VERSION ""

NS_ :

BS_:

BU_: Bat1 OpticalSensor TelemetryNode Master SensorF SensorR BrakeF BrakeR PDU TestBench MDB1 MDB2 MDB3 MDB4 MDB5 MDB6 Track CLU

BO_ 57 CLU_TX_ActionRequest: 5 CLU
 SG_ CLU_TX_TagetAirGap : 8|32@1+ (1,0) [0|4294967295] "" Vector__XXX
 SG_ CLU_TX_ActionRequest : 0|8@1+ (1,0) [0|255] "" Vector__XXX

BO_ 564 CLU_RX_ActionRequest: 1 SensorF
 SG_ CLU_RX_ActionRequest : 0|8@1+ (1,0) [0|255] ""  SensorF

BO_ 2165346838 BMS44_2_Frame: 8 Vector__XXX
 SG_ BMS44_2_FramePayload : 0|64@1+ (1,0) [0|0] ""  SensorF

BO_ 1792 CLU_RX_StatusLedControll: 1 SensorF
 SG_ CLU_RX_ErrorStatus : 0|1@1+ (1,0) [0|1] ""  CLU

BO_ 592 CLU_TX_LevitationState: 1 CLU
 SG_ CLU_LevitationState : 0|8@1+ (1,0) [0|255] ""  SensorF

BO_ 768 CLU_TX_CoolingState: 1 Vector__XXX
 SG_ CLU_RequiresCooling : 0|1@1+ (1,0) [0|1] ""  SensorF

BO_ 274 MDB3_RX_TargetAirGap: 4 CLU
 SG_ MDB3_TargetAirGap : 0|32@1+ (1,0) [0|0] "" Vector__XXX

BO_ 295 MDB6_RX_TargetAirGap: 4 CLU
 SG_ MDB6_TargetAirGap : 0|32@1+ (1,0) [0|0] "" Vector__XXX

BO_ 297 MDB6_TX_Temperature: 4 Vector__XXX
 SG_ MDB6_Temperature : 0|32@1+ (1,0) [0|0] ""  CLU

BO_ 294 MDB6_TX_AirGap: 4 Vector__XXX
 SG_ MDB6_TargetAirGap : 0|32@1+ (1,0) [0|0] ""  CLU

BO_ 293 MDB6_TX_State: 1 Vector__XXX
 SG_ MDB6_State : 0|8@1+ (1,0) [0|255] ""  CLU

BO_ 292 MDB5_TX_Temperature: 4 Vector__XXX
 SG_ MDB5_Temperature : 0|32@1+ (1,0) [0|0] ""  CLU

BO_ 290 MDB5_RX_TargetAirGap: 4 CLU
 SG_ MDB5_TargetAirGap : 0|32@1+ (1,0) [0|0] "" Vector__XXX

BO_ 289 MDB5_TX_AirGap: 4 Vector__XXX
 SG_ MDB5_AirGap : 0|32@1+ (1,0) [0|0] ""  CLU

BO_ 288 MDB5_TX_State: 1 Vector__XXX
 SG_ MDB5_State : 0|8@1+ (1,0) [0|255] ""  CLU

BO_ 281 MDB4_TX_Temperature: 4 Vector__XXX
 SG_ MDB4_Temperature : 0|32@1+ (1,0) [0|0] ""  CLU

BO_ 279 MDB4_RX_TargetAirGap: 4 CLU
 SG_ MDB4_TargetAirGap : 0|32@1+ (1,0) [0|0] "" Vector__XXX

BO_ 278 MDB4_TX_AirGap: 4 Vector__XXX
 SG_ MDB4_AirGap : 0|32@1+ (1,0) [0|0] ""  CLU

BO_ 277 MDB4_TX_State: 1 Vector__XXX
 SG_ MDB4_State : 0|8@1+ (1,0) [0|255] ""  CLU

BO_ 276 MDB3_TX_Temperature: 4 Vector__XXX
 SG_ MDB3_Temperature : 0|32@1+ (1,0) [0|0] ""  CLU

BO_ 273 MDB3_TX_AirGap: 4 Vector__XXX
 SG_ MDB3_AirGap : 0|32@1+ (1,0) [0|0] ""  CLU

BO_ 272 MDB3_TX_State: 1 Vector__XXX
 SG_ MDB3_State : 0|8@1+ (1,0) [0|255] ""  CLU

BO_ 265 MDB2_TX_Temperature: 4 Vector__XXX
 SG_ MDB2_Temperature : 0|32@1+ (1,0) [0|0] ""  CLU

BO_ 263 MDB2_RX_TargetAirGap: 4 CLU
 SG_ MDB2_TargetAirGap : 0|32@1+ (1,0) [0|0] "" Vector__XXX

BO_ 262 MDB2_TX_AirGap: 4 Vector__XXX
 SG_ MDB2_AirGap : 0|32@1+ (1,0) [0|0] ""  CLU

BO_ 261 MDB2_TX_State: 1 Vector__XXX
 SG_ MDB2_State : 0|8@1+ (1,0) [0|255] ""  CLU

BO_ 258 MDB1_RX_TargetAirGap: 4 CLU
 SG_ MDB1_TargetAirGap : 0|32@1+ (1,0) [0|0] "" Vector__XXX

BO_ 260 MDB1_TX_Temperature: 4 MDB3
 SG_ MDB1_Temperature : 0|32@1+ (1,0) [0|0] ""  CLU,SensorF

BO_ 257 MDB1_TX_AirGap: 4 MDB3
 SG_ MDB1_AirGap : 0|32@1+ (1,0) [0|0] ""  CLU

BO_ 1041 BrakeF_TX_PressureCooling: 2 BrakeF
 SG_ BrakeF_TX_Pressure_Reservoir : 0|12@1+ (0.005,-2) [-2|18.475] "bar"  SensorF

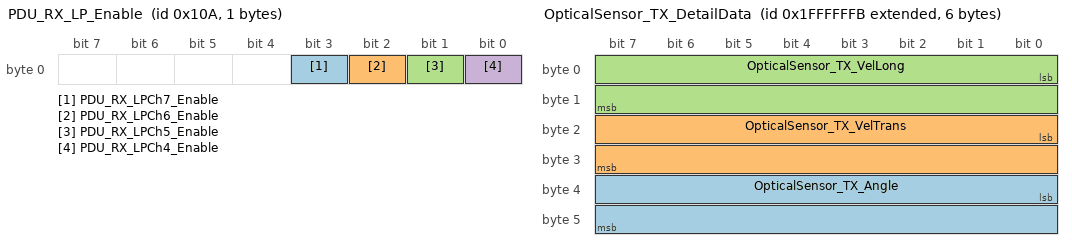
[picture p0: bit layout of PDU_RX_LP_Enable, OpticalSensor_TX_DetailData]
BO_ 266 PDU_RX_LP_Enable: 1 PDU
 SG_ PDU_RX_LPCh7_Enable : 3|1@1+ (1,0) [0|1] ""  SensorF
 SG_ PDU_RX_LPCh6_Enable : 2|1@1+ (1,0) [0|1] ""  SensorF
 SG_ PDU_RX_LPCh5_Enable : 1|1@1+ (1,0) [0|1] ""  SensorF
 SG_ PDU_RX_LPCh4_Enable : 0|1@1+ (1,0) [0|1] ""  SensorF

BO_ 2148592864 BMS44_1_Frame: 8 Bat1
 SG_ BMS44_1_FramePayload : 0|64@1+ (1,0) [0|0] ""  SensorF

BO_ 1 Track_TX_Respond: 1 Track
 SG_ Track_TX_Response : 0|8@1+ (1,0) [0|255] ""  SensorF

BO_ 0 Track_RX_Controll: 1 SensorF
 SG_ Track_RX_Command : 0|8@1+ (1,0) [0|255] "" Vector__XXX

BO_ 512 TEST_GROUND_STATION_CONTROLL: 1 Vector__XXX
 SG_ TEST_GROUND_STATION_COMMAND : 0|8@1+ (1,0) [0|255] ""  SensorF

BO_ 256 MDB1_TX_State: 1 MDB3
 SG_ MDB1_State : 0|8@1+ (1,0) [0|255] ""  CLU,SensorF

BO_ 450 SensorR_RX_POD1: 8 Vector__XXX

BO_ 2684354555 OpticalSensor_TX_DetailData: 6 OpticalSensor
 SG_ OpticalSensor_TX_Angle : 32|16@1- (0.01,0) [-45|45] "�" Vector__XXX
 SG_ OpticalSensor_TX_VelTrans : 16|16@1- (0.036,0) [-200|200] "km/h" Vector__XXX
 SG_ OpticalSensor_TX_VelLong : 0|16@1+ (0.036,0) [0|400] "km/h" Vector__XXX

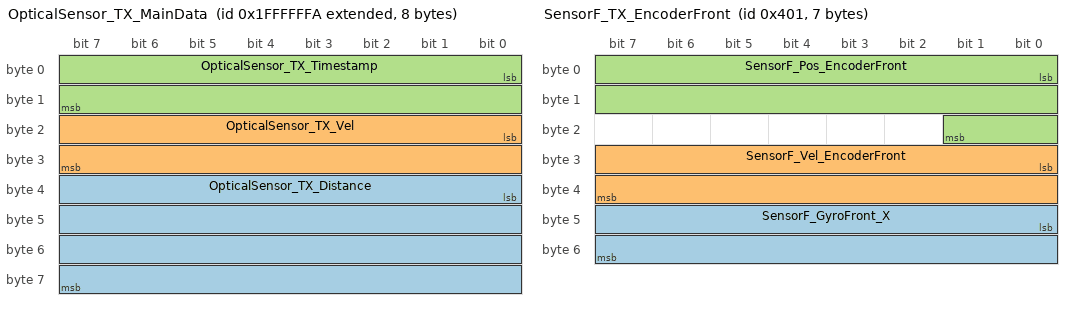
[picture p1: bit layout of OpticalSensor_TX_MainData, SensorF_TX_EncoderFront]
BO_ 2684354554 OpticalSensor_TX_MainData: 8 OpticalSensor
 SG_ OpticalSensor_TX_Distance : 32|32@1+ (0.001,0) [0|4294970] "m"  SensorF,SensorR
 SG_ OpticalSensor_TX_Vel : 16|16@1+ (0.036,0) [0|400] "km/h"  SensorF,SensorR
 SG_ OpticalSensor_TX_Timestamp : 0|16@1+ (1,0) [0|65535] ""  SensorF,SensorR

BO_ 2684354556 OpticalSensor_TX_Status: 8 OpticalSensor
 SG_ OpticalSensor_TX_VddOK : 62|1@1+ (1,0) [0|0] ""  SensorF
 SG_ OpticalSensor_TX_VeeOK : 61|1@1+ (1,0) [0|0] ""  SensorF
 SG_ OpticalSensor_TX_V33OK : 60|1@1+ (1,0) [0|0] ""  SensorF
 SG_ OpticalSensor_TX_V25OK : 59|1@1+ (1,0) [0|0] ""  SensorF
 SG_ OpticalSensor_TX_LEDStatus : 57|2@1+ (1,0) [0|0] ""  SensorF
 SG_ OpticalSensor_TX_LED_Cal : 56|1@1+ (1,0) [0|0] ""  SensorF
 SG_ OpticalSensor_TX_PowerOK : 55|1@1+ (1,0) [0|0] ""  SensorF
 SG_ OpticalSensor_TX_CurrentOK : 54|1@1+ (1,0) [0|0] ""  SensorF
 SG_ OpticalSensor_TX_CurrentLowHigh : 53|1@1+ (1,0) [0|0] ""  SensorF
 SG_ OpticalSensor_TX_OpticOK : 52|1@1+ (1,0) [0|0] ""  SensorF
 SG_ OpticalSensor_TX_TempOK : 51|1@1+ (1,0) [0|0] ""  SensorF
 SG_ OpticalSensor_TX_SensorOK : 50|1@1+ (1,0) [0|0] ""  SensorF
 SG_ OpticalSensor_TX_SelfTest : 49|1@1+ (1,0) [0|0] ""  SensorF
 SG_ OpticalSensor_TX_STST : 48|1@1+ (1,0) [0|0] ""  SensorF
 SG_ OpticalSensor_TX_LEDCurrent : 40|8@1+ (0.01,0) [0|2.55] "A"  SensorF
 SG_ OpticalSensor_TX_Temp : 32|8@1- (1,0) [-128|127] "�C"  SensorF
 SG_ OpticalSensor_TX_SensorNo : 24|8@1+ (1,0) [0|0] ""  SensorF
 SG_ OpticalSensor_TX_SerialNo : 0|24@1+ (1,0) [0|0] ""  SensorF

BO_ 2 CANzero_NMT: 4 Master
 SG_ CANzero_NMT_Node : 16|16@1+ (1,0) [0|63] ""  SensorF,SensorR,BrakeF,BrakeR,PDU,TelemetryNode,MDB1,MDB2,MDB3,MDB4,MDB5,MDB6,Track,CLU
 SG_ CANzero_NMT_State : 0|16@1+ (1,0) [0|0] ""  SensorF,SensorR,BrakeF,BrakeR,PDU,TelemetryNode,MDB1,MDB2,MDB3,MDB4,MDB5,MDB6,Track,CLU

BO_ 122 CANzero_Sync: 0 Master

BO_ 123 CANzero_Timestamp: 0 Master

BO_ 129 SensorF_EMCY: 4 SensorF

BO_ 385 SensorF_TX_StatePod: 1 SensorF
 SG_ SensorF_TX_PodState : 0|8@1+ (1,0) [0|255] ""  CLU,Track,BrakeF,PDU

BO_ 449 SensorF_RX_PDO1: 0 Vector__XXX

BO_ 513 SensorF_TX_FSMTransitions: 4 SensorF
 SG_ SensorF_TX_PreopHVCUT : 24|1@1+ (1,0) [0|0] "" Vector__XXX
 SG_ SensorF_TX_PreopPDUT : 16|1@1+ (1,0) [0|0] "" Vector__XXX
 SG_ SensorF_TX_PreopBrakeRT : 15|1@1+ (1,0) [0|0] "" Vector__XXX
 SG_ SensorF_TX_PreopBrakeFT : 14|1@1+ (1,0) [0|0] "" Vector__XXX
 SG_ SensorF_TX_PreopSensorRT : 13|1@1+ (1,0) [0|0] "" Vector__XXX
 SG_ SensorF_TX_EnableSensorRT : 12|1@1+ (1,0) [0|0] "" Vector__XXX
 SG_ SensorF_TX_EnablePDUT : 11|1@1+ (1,0) [0|0] "" Vector__XXX
 SG_ SensorF_TX_EnableHVCUT : 10|1@1+ (1,0) [0|0] "" Vector__XXX
 SG_ SensorF_TX_EnableBrakeRT : 9|1@1+ (1,0) [0|0] "" Vector__XXX
 SG_ SensorF_TX_EnableBrakeFT : 8|1@1+ (1,0) [0|0] "" Vector__XXX
 SG_ SensorF_TX_SetHVTransition : 7|1@1+ (1,0) [0|0] "" Vector__XXX
 SG_ SensorF_TX_PreopTransition : 6|1@1+ (1,0) [0|0] "" Vector__XXX
 SG_ SensorF_TX_LaunchStartTransition : 5|1@1+ (1,0) [0|0] "" Vector__XXX
 SG_ SensorF_TX_LaunchSetupTransition : 4|1@1+ (1,0) [0|0] "" Vector__XXX
 SG_ SensorF_TX_HWEnableTransition : 3|1@1+ (1,0) [0|0] "" Vector__XXX
 SG_ SensorF_TX_ErrorResetTransition : 2|1@1+ (1,0) [0|0] "" Vector__XXX
 SG_ SensorF_TX_EnableTransition : 1|1@1+ (1,0) [0|0] "" Vector__XXX
 SG_ SensorF_TX_BrakesTransition : 0|1@1+ (1,0) [0|0] "" Vector__XXX

BO_ 577 SensorF_RX_PDO2: 0 Vector__XXX

BO_ 641 SensorF_TX_PDO3: 0 SensorF

BO_ 705 SensorF_RX_PDO3: 0 Vector__XXX

BO_ 769 SensorF_TX_PDO4: 0 SensorF

BO_ 833 SensorF_RX_PDO4: 0 Vector__XXX

BO_ 897 SensorF_TX_PDO5: 0 SensorF

BO_ 961 SensorF_TX_PDO6: 0 SensorF

BO_ 1025 SensorF_TX_EncoderFront: 7 SensorF
 SG_ SensorF_GyroFront_X : 40|16@1- (0.017,0) [-557.056|557.039] "°/s"  SensorR
 SG_ SensorF_Vel_EncoderFront : 24|16@1- (0.002,0) [-65.536|65.534] "m/s"  SensorR
 SG_ SensorF_Pos_EncoderFront : 0|18@1- (0.005,0) [-655.36|655.355] "m"  SensorR

BO_ 1089 SensorF_TX_BMS: 2 SensorF
 SG_ SensorF_TX_BatteryTemp : 0|12@1+ (0.05,-30) [-30|174.75] "C"  PDU

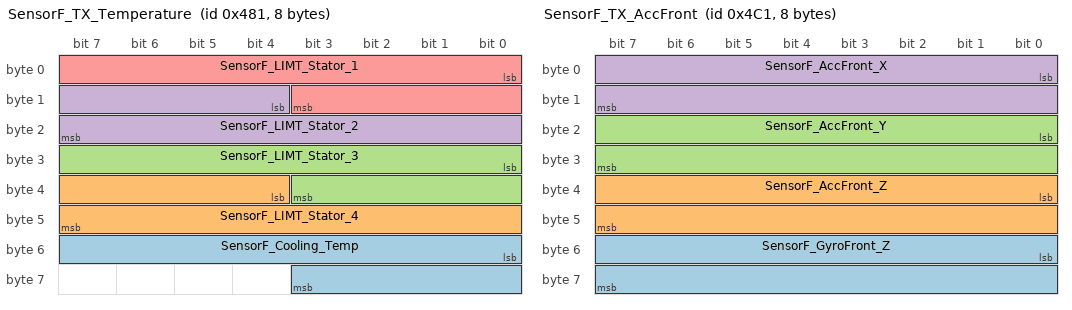
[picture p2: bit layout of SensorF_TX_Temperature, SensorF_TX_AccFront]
BO_ 1153 SensorF_TX_Temperature: 8 SensorF
 SG_ SensorF_Cooling_Temp : 48|12@1+ (0.05,-30) [-30|174.75] "C"  PDU
 SG_ SensorF_LIMT_Stator_4 : 36|12@1+ (0.075,-20) [-20|287.125] "�C" Vector__XXX
 SG_ SensorF_LIMT_Stator_3 : 24|12@1+ (0.075,-20) [-20|287.125] "�C" Vector__XXX
 SG_ SensorF_LIMT_Stator_2 : 12|12@1+ (0.075,-20) [-20|287.125] "�C" Vector__XXX
 SG_ SensorF_LIMT_Stator_1 : 0|12@1+ (0.075,-20) [-20|287.125] "�C" Vector__XXX

BO_ 1217 SensorF_TX_AccFront: 8 SensorF
 SG_ SensorF_GyroFront_Z : 48|16@1- (0.017,0) [-557.056|557.039] "°/s"  SensorR
 SG_ SensorF_AccFront_Z : 32|16@1- (0.00125,0) [-40.96|40.95875] "m/s^2"  SensorR
 SG_ SensorF_AccFront_Y : 16|16@1- (0.00125,0) [-40.96|40.95875] "m/s^2"  SensorR
 SG_ SensorF_AccFront_X : 0|16@1- (0.00125,0) [-40.96|40.95875] "m/s^2"  SensorR

BO_ 1281 SensorF_TX_PDO11: 0 SensorF

BO_ 1345 SensorF_TX_PDO12: 0 SensorF

BO_ 1409 SensorF_SDO_Resp: 8 SensorF
 SG_ SensorF_SDO_RespCode : 12|4@1+ (1,0) [0|0] ""  TelemetryNode
 SG_ SensorF_SDO_ID M : 0|12@1+ (1,0) [0|4095] ""  TelemetryNode

BO_ 1473 SensorF_SDO_Req_Up: 8 TelemetryNode
 SG_ SensorF_SDO_ID M : 0|12@1+ (1,0) [0|4095] ""  SensorF

BO_ 1537 SensorF_SDO_Req_Down: 2 TelemetryNode
 SG_ SensorF_SDO_ID M : 0|12@1+ (1,0) [0|4095] ""  SensorF

BO_ 1793 SensorF_Heartbeat: 1 SensorF
 SG_ SensorF_NodeState : 0|8@1+ (1,0) [0|0] ""  SensorF,Master,TelemetryNode

BO_ 1857 SensorF_BTL_TX: 8 SensorF

BO_ 1921 SensorF_BTL_RX: 8 TelemetryNode

BO_ 130 SensorR_EMCY: 4 SensorR

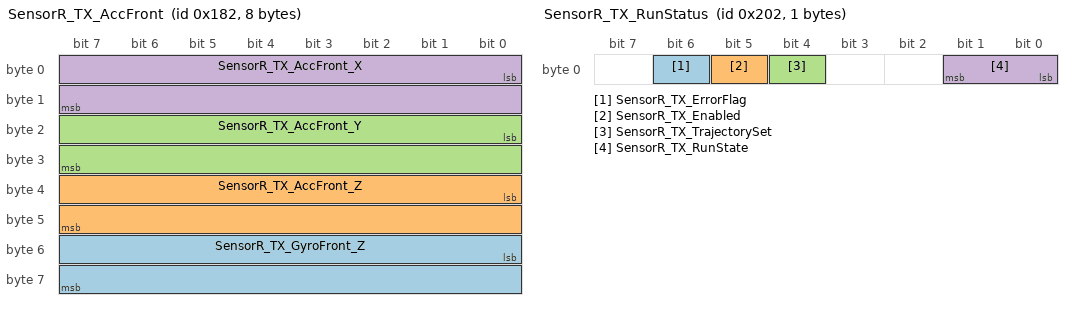
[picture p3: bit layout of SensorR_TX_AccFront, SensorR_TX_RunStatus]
BO_ 386 SensorR_TX_AccFront: 8 SensorR
 SG_ SensorR_TX_GyroFront_Z : 48|16@1- (0.017,0) [-557.056|557.039] "°/s" Vector__XXX
 SG_ SensorR_TX_AccFront_Z : 32|16@1- (0.00125,0) [-40.96|40.95875] "m/s^2" Vector__XXX
 SG_ SensorR_TX_AccFront_Y : 16|16@1- (0.00125,0) [-40.96|40.95875] "m/s^2" Vector__XXX
 SG_ SensorR_TX_AccFront_X : 0|16@1- (0.00125,0) [-40.96|40.95875] "m/s^2" Vector__XXX

BO_ 514 SensorR_TX_RunStatus: 1 SensorR
 SG_ SensorR_TX_ErrorFlag : 6|1@1+ (1,0) [0|0] "" Vector__XXX
 SG_ SensorR_TX_Enabled : 5|1@1+ (1,0) [0|0] "" Vector__XXX
 SG_ SensorR_TX_TrajectorySet : 4|1@1+ (1,0) [0|0] "" Vector__XXX
 SG_ SensorR_TX_RunState : 0|2@1+ (1,0) [0|0] ""  PDU

BO_ 578 SensorR_RX_PDO2: 0 Vector__XXX

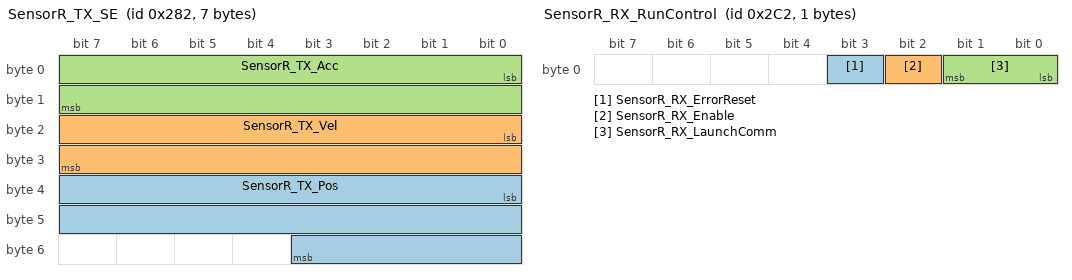
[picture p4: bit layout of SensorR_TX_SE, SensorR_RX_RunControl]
BO_ 642 SensorR_TX_SE: 7 SensorR
 SG_ SensorR_TX_Pos : 32|20@1- (0.001,0) [-524.288|524.287] "m"  PDU,TelemetryNode
 SG_ SensorR_TX_Vel : 16|16@1- (0.002,0) [-65.536|65.534] "m/s"  PDU,TelemetryNode
 SG_ SensorR_TX_Acc : 0|16@1- (0.00125,0) [-40.96|40.95875] "m/s^2"  PDU,TelemetryNode

BO_ 706 SensorR_RX_RunControl: 1 SensorF
 SG_ SensorR_RX_ErrorReset : 3|1@1+ (1,0) [0|0] "" Vector__XXX
 SG_ SensorR_RX_Enable : 2|1@1+ (1,0) [0|0] "" Vector__XXX
 SG_ SensorR_RX_LaunchComm : 0|2@1+ (1,0) [0|0] "" Vector__XXX

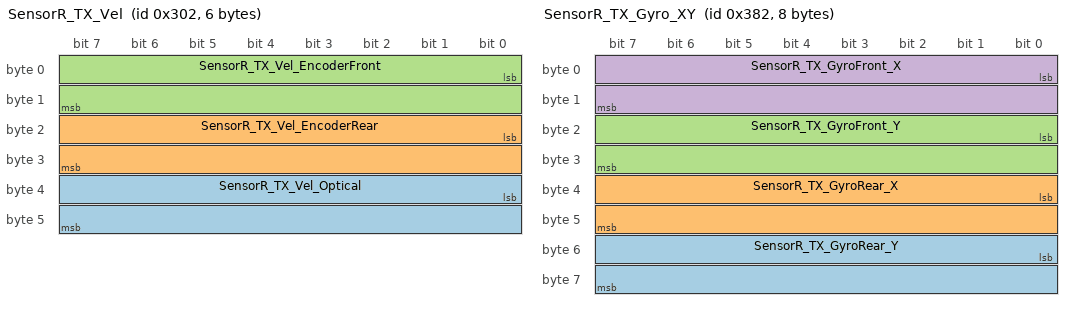
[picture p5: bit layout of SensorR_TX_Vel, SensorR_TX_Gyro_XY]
BO_ 770 SensorR_TX_Vel: 6 SensorR
 SG_ SensorR_TX_Vel_Optical : 32|16@1- (0.002,0) [-65.536|65.534] "m/s" Vector__XXX
 SG_ SensorR_TX_Vel_EncoderRear : 16|16@1- (0.002,0) [-65.536|65.534] "m/s" Vector__XXX
 SG_ SensorR_TX_Vel_EncoderFront : 0|16@1- (0.002,0) [-65.536|65.534] "m/s" Vector__XXX

BO_ 834 SensorR_RX_PDO4: 0 Vector__XXX

BO_ 898 SensorR_TX_Gyro_XY: 8 SensorR
 SG_ SensorR_TX_GyroRear_Y : 48|16@1- (0.017,0) [-557.056|557.039] "°/s" Vector__XXX
 SG_ SensorR_TX_GyroRear_X : 32|16@1- (0.017,0) [-557.056|557.039] "°/s" Vector__XXX
 SG_ SensorR_TX_GyroFront_Y : 16|16@1- (0.017,0) [-557.056|557.039] "°/s" Vector__XXX
 SG_ SensorR_TX_GyroFront_X : 0|16@1- (0.017,0) [-557.056|557.039] "°/s" Vector__XXX

BO_ 962 SensorR_TX_TargetValues: 2 SensorR
 SG_ SensorR_TX_TargetVelocity : 0|14@1- (0.01,0) [-81.92|81.91] "m/s" Vector__XXX

BO_ 1026 SensorR_TX_GapHeight: 4 SensorR
 SG_ SensorR_TX_GapHeight_Right : 12|12@1- (0.0125,0) [-25.6|25.5875] "mm" Vector__XXX
 SG_ SensorR_TX_GapHeight_Left : 0|12@1- (0.0125,0) [-25.6|25.5875] "mm" Vector__XXX

BO_ 1090 SensorR_TX_PDO8: 0 SensorR

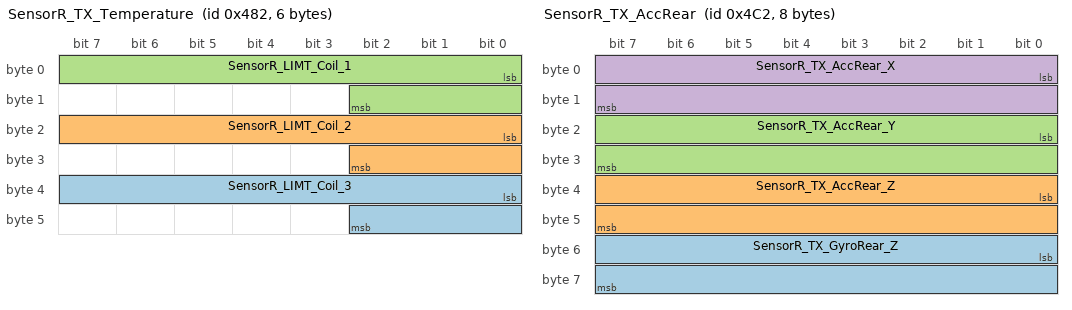
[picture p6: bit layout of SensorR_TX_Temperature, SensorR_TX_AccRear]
BO_ 1154 SensorR_TX_Temperature: 6 SensorR
 SG_ SensorR_LIMT_Coil_3 : 32|11@1+ (0.1,-5) [-5|199.7] "�C"  PDU
 SG_ SensorR_LIMT_Coil_2 : 16|11@1+ (0.1,-5) [-5|199.7] "�C"  PDU
 SG_ SensorR_LIMT_Coil_1 : 0|11@1+ (0.1,-5) [-5|199.7] "�C"  PDU

BO_ 1218 SensorR_TX_AccRear: 8 SensorR
 SG_ SensorR_TX_GyroRear_Z : 48|16@1- (0.017,0) [-557.056|557.039] "°/s" Vector__XXX
 SG_ SensorR_TX_AccRear_Z : 32|16@1- (0.00125,0) [-40.96|40.95875] "m/s^2" Vector__XXX
 SG_ SensorR_TX_AccRear_Y : 16|16@1- (0.00125,0) [-40.96|40.95875] "m/s^2" Vector__XXX
 SG_ SensorR_TX_AccRear_X : 0|16@1- (0.00125,0) [-40.96|40.95875] "m/s^2" Vector__XXX

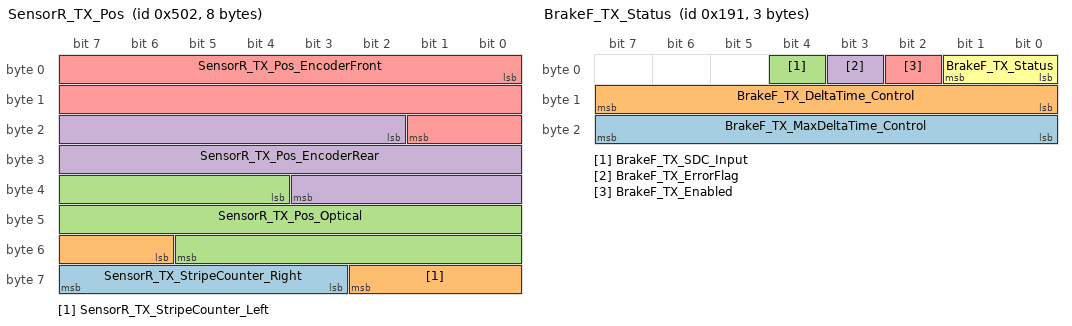
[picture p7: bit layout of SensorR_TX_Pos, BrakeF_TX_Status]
BO_ 1282 SensorR_TX_Pos: 8 SensorR
 SG_ SensorR_TX_StripeCounter_Right : 59|5@1+ (1,0) [0|31] "" Vector__XXX
 SG_ SensorR_TX_StripeCounter_Left : 54|5@1+ (1,0) [0|31] "" Vector__XXX
 SG_ SensorR_TX_Pos_Optical : 36|18@1- (0.005,0) [-655.36|655.355] "m" Vector__XXX
 SG_ SensorR_TX_Pos_EncoderRear : 18|18@1- (0.005,0) [-655.36|655.355] "m" Vector__XXX
 SG_ SensorR_TX_Pos_EncoderFront : 0|18@1- (0.005,0) [-655.36|655.355] "m" Vector__XXX

BO_ 1346 SensorR_TX_PDO12: 0 SensorR

BO_ 1410 SensorR_SDO_Resp: 8 SensorR
 SG_ SensorR_SDO_RespCode : 12|4@1+ (1,0) [0|0] ""  TelemetryNode
 SG_ SensorR_SDO_ID M : 0|12@1+ (1,0) [0|4095] ""  PDU,TelemetryNode

BO_ 1474 SensorR_SDO_Req_Up: 8 TelemetryNode
 SG_ SensorR_SDO_ID M : 0|12@1+ (1,0) [0|4095] ""  SensorR

BO_ 1538 SensorR_SDO_Req_Down: 2 TelemetryNode
 SG_ SensorR_SDO_ID M : 0|12@1+ (1,0) [0|4095] ""  SensorR

BO_ 1794 SensorR_Heartbeat: 1 SensorR
 SG_ SensorR_NodeState : 0|8@1+ (1,0) [0|0] ""  Master,TelemetryNode

BO_ 1858 SensorR_BTL_TX: 8 SensorR

BO_ 1922 SensorR_BTL_RX: 8 TelemetryNode

BO_ 145 BrakeF_EMCY: 4 BrakeF

BO_ 401 BrakeF_TX_Status: 3 BrakeF
 SG_ BrakeF_TX_MaxDeltaTime_Control : 16|8@1+ (1,0) [0|255] "ms" Vector__XXX
 SG_ BrakeF_TX_DeltaTime_Control : 8|8@1+ (1,0) [0|255] "ms" Vector__XXX
 SG_ BrakeF_TX_SDC_Input : 4|1@1+ (1,0) [0|0] "" Vector__XXX
 SG_ BrakeF_TX_ErrorFlag : 3|1@1+ (1,0) [0|0] ""  SensorF
 SG_ BrakeF_TX_Enabled : 2|1@1+ (1,0) [0|0] ""  SensorF
 SG_ BrakeF_TX_Status : 0|2@1+ (1,0) [0|0] ""  SensorF

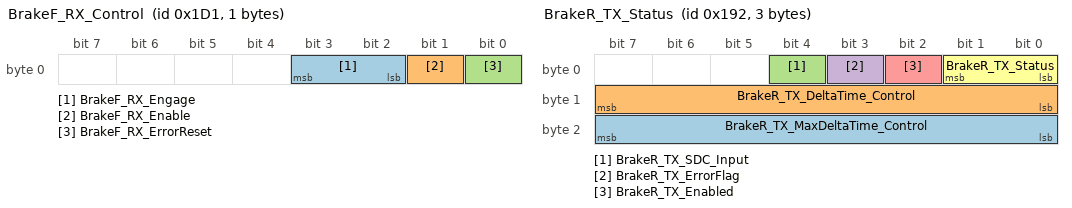
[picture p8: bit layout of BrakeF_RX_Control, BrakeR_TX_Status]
BO_ 465 BrakeF_RX_Control: 1 SensorF
 SG_ BrakeF_RX_Engage : 2|2@1+ (1,0) [0|0] "" Vector__XXX
 SG_ BrakeF_RX_Enable : 1|1@1+ (1,0) [0|0] "" Vector__XXX
 SG_ BrakeF_RX_ErrorReset : 0|1@1+ (1,0) [0|0] "" Vector__XXX

BO_ 529 BrakeF_TX_PDO2: 0 BrakeF

BO_ 593 BrakeF_RX_PDO2: 0 Vector__XXX

BO_ 657 BrakeF_TX_PDO3: 0 BrakeF

BO_ 721 BrakeF_RX_PDO3: 0 Vector__XXX

BO_ 785 BrakeF_TX_PDO4: 0 BrakeF

BO_ 849 BrakeF_RX_PDO4: 0 Vector__XXX

BO_ 913 BrakeF_TX_PDO5: 0 BrakeF

BO_ 977 BrakeF_TX_PDO6: 0 BrakeF

BO_ 1105 BrakeF_TX_PDO8: 0 BrakeF

BO_ 1169 BrakeF_TX_PDO9: 0 BrakeF

BO_ 1233 BrakeF_TX_PDO10: 0 BrakeF

BO_ 1297 BrakeF_TX_PDO11: 0 BrakeF

BO_ 1361 BrakeF_TX_PDO12: 0 BrakeF

BO_ 1425 BrakeF_SDO_Resp: 8 BrakeF
 SG_ BrakeF_SDO_RespCode : 12|4@1+ (1,0) [0|0] ""  TelemetryNode
 SG_ BrakeF_SDO_ID M : 0|12@1+ (1,0) [0|4095] ""  TelemetryNode

BO_ 1489 BrakeF_SDO_Req_Up: 8 TelemetryNode
 SG_ BrakeF_SDO_ID M : 0|12@1+ (1,0) [0|4095] ""  BrakeF

BO_ 1553 BrakeF_SDO_Req_Down: 2 TelemetryNode
 SG_ BrakeF_SDO_ID M : 0|12@1+ (1,0) [0|4095] ""  BrakeF

BO_ 1809 BrakeF_Heartbeat: 1 BrakeF
 SG_ BrakeF_NodeState : 0|8@1+ (1,0) [0|0] ""  SensorF,Master,TelemetryNode

BO_ 1873 BrakeF_BTL_TX: 8 BrakeF

BO_ 1937 BrakeF_BTL_RX: 8 TelemetryNode

BO_ 146 BrakeR_EMCY: 4 BrakeR

BO_ 402 BrakeR_TX_Status: 3 BrakeR
 SG_ BrakeR_TX_MaxDeltaTime_Control : 16|8@1+ (1,0) [0|255] "ms" Vector__XXX
 SG_ BrakeR_TX_DeltaTime_Control : 8|8@1+ (1,0) [0|255] "ms" Vector__XXX
 SG_ BrakeR_TX_SDC_Input : 4|1@1+ (1,0) [0|0] "" Vector__XXX
 SG_ BrakeR_TX_ErrorFlag : 3|1@1+ (1,0) [0|0] "" Vector__XXX
 SG_ BrakeR_TX_Enabled : 2|1@1+ (1,0) [0|0] "" Vector__XXX
 SG_ BrakeR_TX_Status : 0|2@1+ (1,0) [0|0] "" Vector__XXX

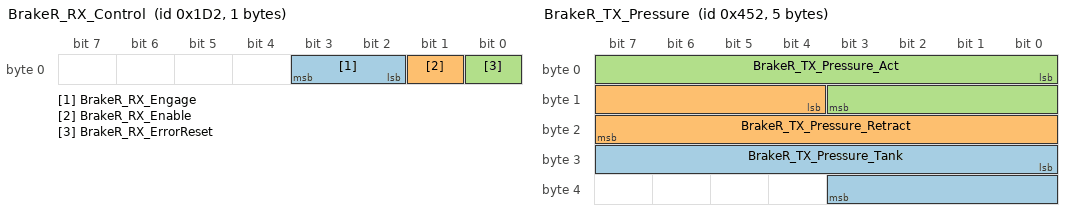
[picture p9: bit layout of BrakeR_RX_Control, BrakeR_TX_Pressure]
BO_ 466 BrakeR_RX_Control: 1 SensorF
 SG_ BrakeR_RX_Engage : 2|2@1+ (1,0) [0|0] "" Vector__XXX
 SG_ BrakeR_RX_Enable : 1|1@1+ (1,0) [0|0] "" Vector__XXX
 SG_ BrakeR_RX_ErrorReset : 0|1@1+ (1,0) [0|0] "" Vector__XXX

BO_ 530 BrakeR_TX_PDO2: 0 BrakeR

BO_ 594 BrakeR_RX_PDO2: 0 Vector__XXX

BO_ 658 BrakeR_TX_PDO3: 0 BrakeR

BO_ 722 BrakeR_RX_PDO3: 0 Vector__XXX

BO_ 786 BrakeR_TX_PDO4: 0 BrakeR

BO_ 850 BrakeR_RX_PDO4: 0 Vector__XXX

BO_ 914 BrakeR_TX_PDO5: 0 BrakeR

BO_ 978 BrakeR_TX_PDO6: 0 BrakeR

BO_ 1042 BrakeR_TX_PDO7: 0 BrakeR

BO_ 1106 BrakeR_TX_Pressure: 5 BrakeR
 SG_ BrakeR_TX_Pressure_Tank : 24|12@1+ (0.005,-2) [-2|18.475] "bar" Vector__XXX
 SG_ BrakeR_TX_Pressure_Retract : 12|12@1+ (0.005,-2) [-2|18.475] "bar" Vector__XXX
 SG_ BrakeR_TX_Pressure_Act : 0|12@1+ (0.005,-2) [-2|18.475] "bar" Vector__XXX

BO_ 1170 BrakeR_TX_PDO9: 0 BrakeR

BO_ 1234 BrakeR_TX_PDO10: 0 BrakeR

BO_ 1298 BrakeR_TX_PDO11: 0 BrakeR

BO_ 1362 BrakeR_TX_PDO12: 0 BrakeR

BO_ 1426 BrakeR_SDO_Resp: 8 BrakeR
 SG_ BrakeR_SDO_RespCode : 12|4@1+ (1,0) [0|0] ""  TelemetryNode
 SG_ BrakeR_SDO_ID M : 0|12@1+ (1,0) [0|4095] ""  TelemetryNode

BO_ 1490 BrakeR_SDO_Req_Up: 8 TelemetryNode
 SG_ BrakeR_SDO_ID M : 0|12@1+ (1,0) [0|4095] ""  BrakeR

BO_ 1554 BrakeR_SDO_Req_Down: 2 TelemetryNode
 SG_ BrakeR_SDO_ID M : 0|12@1+ (1,0) [0|4095] ""  BrakeR

BO_ 1810 BrakeR_Heartbeat: 1 BrakeR
 SG_ BrakeR_NodeState : 0|8@1+ (1,0) [0|0] ""  Master,TelemetryNode

BO_ 1874 BrakeR_BTL_TX: 8 BrakeR

BO_ 1938 BrakeR_BTL_RX: 8 TelemetryNode

BO_ 154 PDU_EMCY: 4 PDU

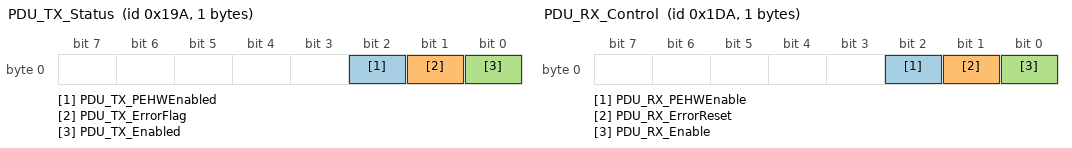
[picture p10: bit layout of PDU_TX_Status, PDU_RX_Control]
BO_ 410 PDU_TX_Status: 1 PDU
 SG_ PDU_TX_PEHWEnabled : 2|1@1+ (1,0) [0|0] ""  SensorF
 SG_ PDU_TX_ErrorFlag : 1|1@1+ (1,0) [0|0] ""  SensorF
 SG_ PDU_TX_Enabled : 0|1@1+ (1,0) [0|0] ""  SensorF

BO_ 474 PDU_RX_Control: 1 SensorF
 SG_ PDU_RX_PEHWEnable : 2|1@1+ (1,0) [0|0] ""  PDU
 SG_ PDU_RX_ErrorReset : 1|1@1+ (1,0) [0|0] ""  PDU
 SG_ PDU_RX_Enable : 0|1@1+ (1,0) [0|0] ""  PDU

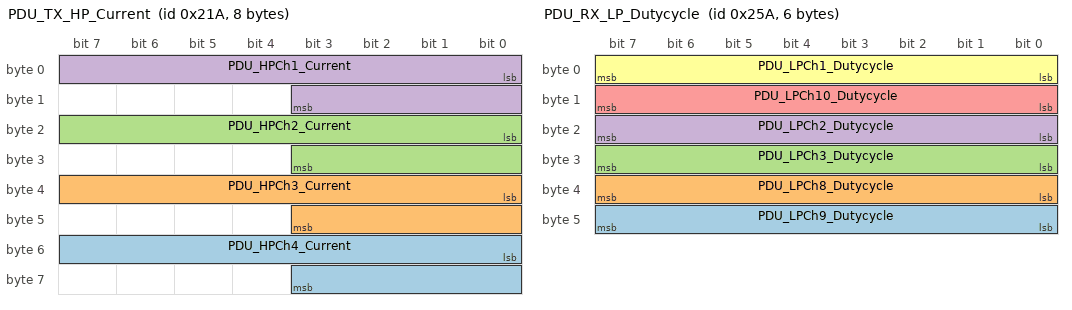
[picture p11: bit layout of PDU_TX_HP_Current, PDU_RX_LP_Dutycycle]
BO_ 538 PDU_TX_HP_Current: 8 PDU
 SG_ PDU_HPCh4_Current : 48|12@1+ (0.004,0) [0|16.38] "A"  SensorF
 SG_ PDU_HPCh3_Current : 32|12@1+ (0.004,0) [0|16.38] "A"  SensorF
 SG_ PDU_HPCh2_Current : 16|12@1+ (0.004,0) [0|16.38] "A"  SensorF
 SG_ PDU_HPCh1_Current : 0|12@1+ (0.004,0) [0|16.38] "A"  SensorF

BO_ 602 PDU_RX_LP_Dutycycle: 6 SensorF
 SG_ PDU_LPCh9_Dutycycle : 40|8@1+ (0.5,0) [0|100] "%" Vector__XXX
 SG_ PDU_LPCh8_Dutycycle : 32|8@1+ (0.5,0) [0|100] "%" Vector__XXX
 SG_ PDU_LPCh3_Dutycycle : 24|8@1+ (0.5,0) [0|100] "%" Vector__XXX
 SG_ PDU_LPCh2_Dutycycle : 16|8@1+ (0.5,0) [0|100] "%" Vector__XXX
 SG_ PDU_LPCh10_Dutycycle : 8|8@1+ (0.5,0) [0|100] "%" Vector__XXX
 SG_ PDU_LPCh1_Dutycycle : 0|8@1+ (0.5,0) [0|100] "%" Vector__XXX

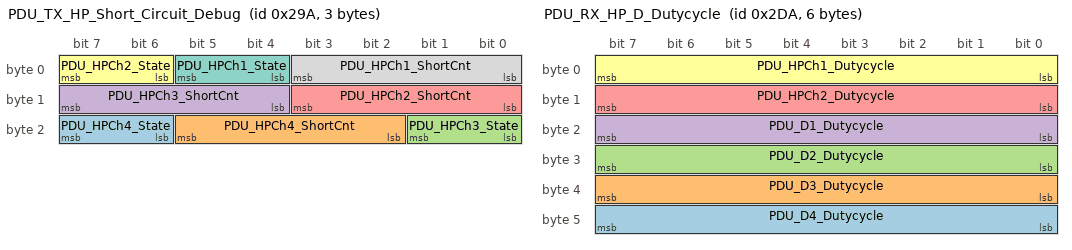
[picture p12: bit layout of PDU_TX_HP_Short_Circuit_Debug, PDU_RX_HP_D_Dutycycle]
BO_ 666 PDU_TX_HP_Short_Circuit_Debug: 3 PDU
 SG_ PDU_HPCh4_State : 22|2@1+ (1,0) [0|3] "" Vector__XXX
 SG_ PDU_HPCh4_ShortCnt : 18|4@1+ (1,0) [0|15] "" Vector__XXX
 SG_ PDU_HPCh3_State : 16|2@1+ (1,0) [0|3] "" Vector__XXX
 SG_ PDU_HPCh3_ShortCnt : 12|4@1+ (1,0) [0|15] "" Vector__XXX
 SG_ PDU_HPCh2_ShortCnt : 8|4@1+ (1,0) [0|15] "" Vector__XXX
 SG_ PDU_HPCh2_State : 6|2@1+ (1,0) [0|3] "" Vector__XXX
 SG_ PDU_HPCh1_State : 4|2@1+ (1,0) [0|3] "" Vector__XXX
 SG_ PDU_HPCh1_ShortCnt : 0|4@1+ (1,0) [0|15] "" Vector__XXX

BO_ 730 PDU_RX_HP_D_Dutycycle: 6 SensorF
 SG_ PDU_D4_Dutycycle : 40|8@1+ (0.5,0) [0|100] "%" Vector__XXX
 SG_ PDU_D3_Dutycycle : 32|8@1+ (0.5,0) [0|100] "%" Vector__XXX
 SG_ PDU_D2_Dutycycle : 24|8@1+ (0.5,0) [0|100] "%" Vector__XXX
 SG_ PDU_D1_Dutycycle : 16|8@1+ (0.5,0) [0|100] "%" Vector__XXX
 SG_ PDU_HPCh2_Dutycycle : 8|8@1+ (0.5,0) [0|100] "%" Vector__XXX
 SG_ PDU_HPCh1_Dutycycle : 0|8@1+ (0.5,0) [0|100] "%" Vector__XXX

BO_ 794 PDU_TX_PDO4: 0 PDU

BO_ 858 PDU_RX_Manual_Control: 3 Vector__XXX
 SG_ PDU_SDC_Enable : 18|1@1+ (1,0) [0|0] "" Vector__XXX
 SG_ PDU_D4_Enable : 17|1@1+ (1,0) [0|1] "" Vector__XXX
 SG_ PDU_D3_Enable : 16|1@1+ (1,0) [0|1] "" Vector__XXX
 SG_ PDU_D2_Enable : 15|1@1+ (1,0) [0|1] "" Vector__XXX
 SG_ PDU_D1_Enable : 14|1@1+ (1,0) [0|1] "" Vector__XXX
 SG_ PDU_HPCh4_Enable : 13|1@1+ (1,0) [0|1] "" Vector__XXX
 SG_ PDU_HPCh3_Enable : 12|1@1+ (1,0) [0|1] "" Vector__XXX
 SG_ PDU_HPCh2_Enable : 11|1@1+ (1,0) [0|1] "" Vector__XXX
 SG_ PDU_HPCh1_Enable : 10|1@1+ (1,0) [0|1] "" Vector__XXX
 SG_ PDU_LPCh10_Enable : 9|1@1+ (1,0) [0|1] "" Vector__XXX
 SG_ PDU_LPCh9_Enable : 8|1@1+ (1,0) [0|1] "" Vector__XXX
 SG_ PDU_LPCh8_Enable : 7|1@1+ (1,0) [0|1] "" Vector__XXX
 SG_ PDU_LPCh7_Enable : 6|1@1+ (1,0) [0|1] "" Vector__XXX
 SG_ PDU_LPCh6_Enable : 5|1@1+ (1,0) [0|1] "" Vector__XXX
 SG_ PDU_LPCh5_Enable : 4|1@1+ (1,0) [0|1] "" Vector__XXX
 SG_ PDU_LPCh4_Enable : 3|1@1+ (1,0) [0|1] "" Vector__XXX
 SG_ PDU_LPCh3_Enable : 2|1@1+ (1,0) [0|1] "" Vector__XXX
 SG_ PDU_LPCh2_Enable : 1|1@1+ (1,0) [0|1] "" Vector__XXX
 SG_ PDU_LPCh1_Enable : 0|1@1+ (1,0) [0|1] "" Vector__XXX

BO_ 922 PDU_TX_PDO5: 0 PDU

BO_ 986 PDU_TX_PDO6: 0 PDU

BO_ 1050 PDU_TX_PDO7: 0 PDU

BO_ 1114 PDU_TX_PDO8: 0 PDU

BO_ 1178 PDU_TX_LP_Short_Circuit_Debug: 8 PDU
 SG_ PDU_LPCh9_State : 58|2@1+ (1,0) [0|3] "" Vector__XXX
 SG_ PDU_LPCh8_State : 56|2@1+ (1,0) [0|3] "" Vector__XXX
 SG_ PDU_LPCh7_State : 54|2@1+ (1,0) [0|3] "" Vector__XXX
 SG_ PDU_LPCh6_State : 52|2@1+ (1,0) [0|3] "" Vector__XXX
 SG_ PDU_LPCh5_State : 50|2@1+ (1,0) [0|3] "" Vector__XXX
 SG_ PDU_LPCh4_State : 48|2@1+ (1,0) [0|3] "" Vector__XXX
 SG_ PDU_LPCh3_State : 46|2@1+ (1,0) [0|3] "" Vector__XXX
 SG_ PDU_LPCh2_State : 44|2@1+ (1,0) [0|3] "" Vector__XXX
 SG_ PDU_LPCh1_State : 42|2@1+ (1,0) [0|3] "" Vector__XXX
 SG_ PDU_LPCh10_State : 40|2@1+ (1,0) [0|3] "" Vector__XXX
 SG_ PDU_LPCh9_ShortCnt : 36|4@1+ (1,0) [0|15] "" Vector__XXX
 SG_ PDU_LPCh8_ShortCnt : 32|4@1+ (1,0) [0|15] "" Vector__XXX
 SG_ PDU_LPCh7_ShortCnt : 28|4@1+ (1,0) [0|15] "" Vector__XXX
 SG_ PDU_LPCh6_ShortCnt : 24|4@1+ (1,0) [0|15] "" Vector__XXX
 SG_ PDU_LPCh5_ShortCnt : 20|4@1+ (1,0) [0|15] "" Vector__XXX
 SG_ PDU_LPCh4_ShortCnt : 16|4@1+ (1,0) [0|15] "" Vector__XXX
 SG_ PDU_LPCh3_ShortCnt : 12|4@1+ (1,0) [0|15] "" Vector__XXX
 SG_ PDU_LPCh2_ShortCnt : 8|4@1+ (1,0) [0|15] "" Vector__XXX
 SG_ PDU_LPCh1_ShortCnt : 4|4@1+ (1,0) [0|15] "" Vector__XXX
 SG_ PDU_LPCh10_ShortCnt : 0|4@1+ (1,0) [0|15] "" Vector__XXX

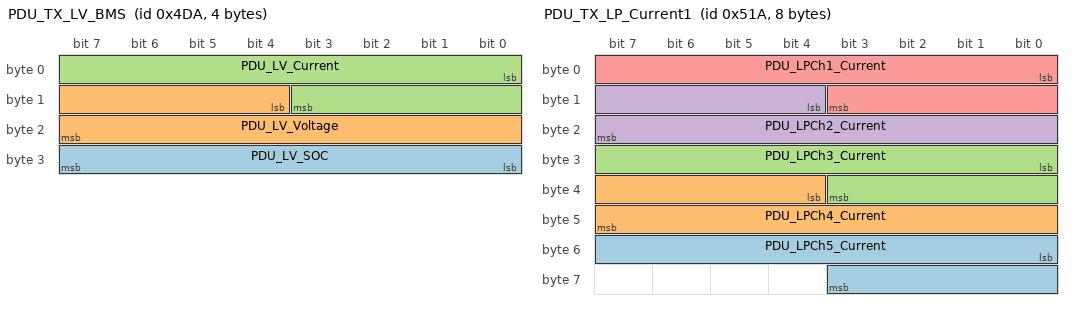
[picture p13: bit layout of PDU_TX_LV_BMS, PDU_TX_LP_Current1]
BO_ 1242 PDU_TX_LV_BMS: 4 PDU
 SG_ PDU_LV_SOC : 24|8@1- (1,0) [0|100] "%" Vector__XXX
 SG_ PDU_LV_Voltage : 12|12@1+ (0.01,0) [0|40.95] "V" Vector__XXX
 SG_ PDU_LV_Current : 0|12@1+ (0.01,0) [0|40.95] "A" Vector__XXX

BO_ 1306 PDU_TX_LP_Current1: 8 PDU
 SG_ PDU_LPCh5_Current : 48|12@1+ (0.002,0) [0|8.19] "A"  SensorF
 SG_ PDU_LPCh4_Current : 36|12@1+ (0.002,0) [0|8.19] "A"  SensorF
 SG_ PDU_LPCh3_Current : 24|12@1+ (0.002,0) [0|8.19] "A"  SensorF
 SG_ PDU_LPCh2_Current : 12|12@1+ (0.002,0) [0|8.19] "A"  SensorF
 SG_ PDU_LPCh1_Current : 0|12@1+ (0.002,0) [0|8.19] "A"  SensorF

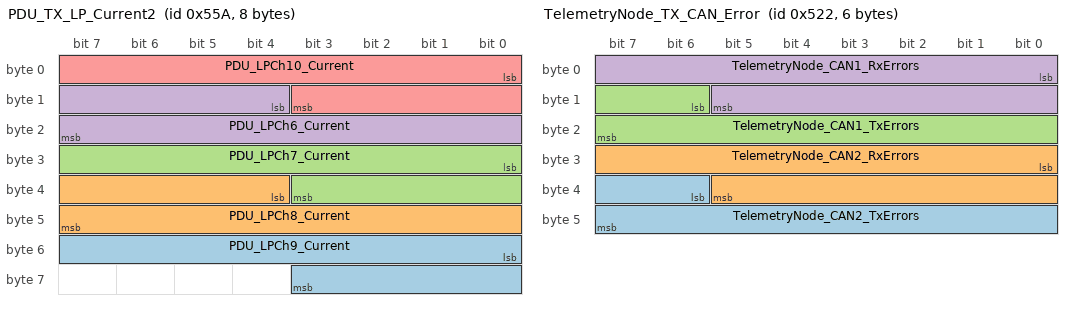
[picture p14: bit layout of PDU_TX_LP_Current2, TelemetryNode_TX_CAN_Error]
BO_ 1370 PDU_TX_LP_Current2: 8 PDU
 SG_ PDU_LPCh9_Current : 48|12@1+ (0.002,0) [0|8.19] "A"  SensorF
 SG_ PDU_LPCh8_Current : 36|12@1+ (0.002,0) [0|8.19] "A"  SensorF
 SG_ PDU_LPCh7_Current : 24|12@1+ (0.002,0) [0|8.19] "A"  SensorF
 SG_ PDU_LPCh6_Current : 12|12@1+ (0.002,0) [0|8.19] "A"  SensorF
 SG_ PDU_LPCh10_Current : 0|12@1+ (0.002,0) [0|8.19] "A"  SensorF

BO_ 1434 PDU_SDO_Resp: 8 PDU
 SG_ PDU_SDO_RespCode : 12|4@1+ (1,0) [0|0] ""  TelemetryNode
 SG_ PDU_SDO_ID M : 0|12@1+ (1,0) [0|4095] ""  TelemetryNode

BO_ 1498 PDU_SDO_Req_Up: 8 TelemetryNode
 SG_ PDU_SDO_ID M : 0|12@1+ (1,0) [0|4095] ""  PDU

BO_ 1562 PDU_SDO_Req_Down: 2 TelemetryNode
 SG_ PDU_SDO_ID M : 0|12@1+ (1,0) [0|4095] ""  PDU

BO_ 1818 PDU_Heartbeat: 1 PDU
 SG_ PDU_NodeState : 0|8@1+ (1,0) [0|0] ""  SensorF,Master,TelemetryNode

BO_ 1882 PDU_BTL_TX: 8 PDU

BO_ 1946 PDU_BTL_RX: 8 TelemetryNode

BO_ 162 TelemetryNode_EMCY: 4 TelemetryNode

BO_ 418 TelemetryNode_TX_PDO1: 0 TelemetryNode

BO_ 482 TelemetryNode_RX_Shutdown: 1 Vector__XXX
 SG_ TelemetryNode_RX_Shutdown : 0|8@1+ (1,0) [0|0] "" Vector__XXX

BO_ 546 TelemetryNode_TX_PDO2: 0 TelemetryNode

BO_ 610 TelemetryNode_RX_PDO2: 0 Vector__XXX

BO_ 674 TelemetryNode_TX_PDO3: 0 TelemetryNode

BO_ 738 TelemetryNode_RX_PDO3: 0 Vector__XXX

BO_ 802 TelemetryNode_TX_PDO4: 0 TelemetryNode

BO_ 866 TelemetryNode_RX_PDO4: 0 Vector__XXX

BO_ 930 TelemetryNode_TX_PDO5: 0 TelemetryNode

BO_ 994 TelemetryNode_TX_PDO6: 0 TelemetryNode

BO_ 1058 TelemetryNode_TX_PDO7: 0 TelemetryNode

BO_ 1122 TelemetryNode_TX_PDO8: 0 TelemetryNode

BO_ 1186 TelemetryNode_TX_PDO9: 0 TelemetryNode

BO_ 1250 TelemetryNode_TX_PDO10: 0 TelemetryNode

BO_ 1314 TelemetryNode_TX_CAN_Error: 6 TelemetryNode
 SG_ TelemetryNode_CAN2_TxErrors : 38|10@1+ (1,0) [0|4095] "" Vector__XXX
 SG_ TelemetryNode_CAN2_RxErrors : 24|14@1+ (1,0) [0|16383] "" Vector__XXX
 SG_ TelemetryNode_CAN1_TxErrors : 14|10@1+ (1,0) [0|4095] "" Vector__XXX
 SG_ TelemetryNode_CAN1_RxErrors : 0|14@1+ (1,0) [0|16383] "" Vector__XXX

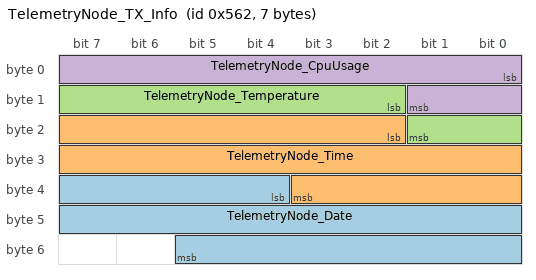
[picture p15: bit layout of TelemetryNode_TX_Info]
BO_ 1378 TelemetryNode_TX_Info: 7 TelemetryNode
 SG_ TelemetryNode_Date : 36|18@1+ (1,20200000) [20200000|20462143] "" Vector__XXX
 SG_ TelemetryNode_Time : 18|18@1+ (1,0) [0|262143] "" Vector__XXX
 SG_ TelemetryNode_Temperature : 10|8@1+ (0.4,-10) [-10|92] "°C" Vector__XXX
 SG_ TelemetryNode_CpuUsage : 0|10@1+ (0.1,0) [0|102.3] "%" Vector__XXX

BO_ 1442 TelemetryNode_SDO_Resp: 8 TelemetryNode
 SG_ TelemetryNode_SDO_RespCode : 12|4@1+ (1,0) [0|0] ""  TelemetryNode
 SG_ TelemetryNode_SDO_ID M : 0|12@1+ (1,0) [0|4095] ""  TelemetryNode

BO_ 1506 TelemetryNode_SDO_Req_Up: 8 TelemetryNode
 SG_ TelemetryNode_SDO_ID M : 0|12@1+ (1,0) [0|4095] ""  TelemetryNode

BO_ 1570 TelemetryNode_SDO_Req_Down: 2 TelemetryNode
 SG_ TelemetryNode_SDO_ID M : 0|12@1+ (1,0) [0|4095] ""  TelemetryNode

BO_ 1826 TelemetryNode_Heartbeat: 1 TelemetryNode
 SG_ TelemetryNode_NodeState : 0|8@1+ (1,0) [0|0] ""  SensorF,Master,TelemetryNode

BO_ 1890 TelemetryNode_BTL_TX: 8 TelemetryNode

BO_ 1954 TelemetryNode_BTL_RX: 8 TelemetryNode

BO_ 161 MDB1_EMCY: 4 MDB1

BO_ 417 MDB1_TX_PDO1: 0 MDB1

BO_ 481 MDB1_RX_PDO1: 0 Vector__XXX

BO_ 545 MDB1_TX_PDO2: 0 MDB1

BO_ 609 MDB1_RX_PDO2: 0 Vector__XXX

BO_ 673 MDB1_TX_PDO3: 0 MDB1

BO_ 737 MDB1_RX_PDO3: 0 Vector__XXX

BO_ 801 MDB1_TX_PDO4: 0 MDB1

BO_ 865 MDB1_RX_PDO4: 0 Vector__XXX

BO_ 929 MDB1_TX_PDO5: 0 MDB1

BO_ 993 MDB1_TX_PDO6: 0 MDB1

BO_ 1057 MDB1_TX_PDO7: 0 MDB1

BO_ 1121 MDB1_TX_PDO8: 0 MDB1

BO_ 1185 MDB1_TX_PDO9: 0 MDB1

BO_ 1249 MDB1_TX_PDO10: 0 MDB1

BO_ 1313 MDB1_TX_PDO11: 0 MDB1

BO_ 1377 MDB1_TX_PDO12: 0 MDB1

BO_ 1441 MDB1_SDO_Resp: 8 MDB1
 SG_ MDB1_SDO_RespCode : 12|4@1+ (1,0) [0|0] ""  TelemetryNode
 SG_ MDB1_SDO_ID M : 0|12@1+ (1,0) [0|4095] ""  TelemetryNode

BO_ 1505 MDB1_SDO_Req_Up: 8 TelemetryNode
 SG_ MDB1_SDO_ID M : 0|12@1+ (1,0) [0|4095] ""  MDB1

BO_ 1569 MDB1_SDO_Req_Down: 2 TelemetryNode
 SG_ MDB1_SDO_ID M : 0|12@1+ (1,0) [0|4095] ""  MDB1

BO_ 1825 MDB1_Heartbeat: 1 MDB1
 SG_ MDB1_NodeState : 0|8@1+ (1,0) [0|0] ""  Master,TelemetryNode

BO_ 1889 MDB1_BTL_TX: 8 MDB1

BO_ 1953 MDB1_BTL_RX: 8 TelemetryNode

BO_ 163 MDB2_EMCY: 4 MDB2

BO_ 419 MDB2_TX_PDO1: 0 MDB2

BO_ 483 MDB2_RX_PDO1: 0 Vector__XXX

BO_ 547 MDB2_TX_PDO2: 0 MDB2

BO_ 611 MDB2_RX_PDO2: 0 Vector__XXX

BO_ 675 MDB2_TX_PDO3: 0 MDB2

BO_ 739 MDB2_RX_PDO3: 0 Vector__XXX

BO_ 803 MDB2_TX_PDO4: 0 MDB2

BO_ 867 MDB2_RX_PDO4: 0 Vector__XXX

BO_ 931 MDB2_TX_PDO5: 0 MDB2

BO_ 995 MDB2_TX_PDO6: 0 MDB2

BO_ 1059 MDB2_TX_PDO7: 0 MDB2

BO_ 1123 MDB2_TX_PDO8: 0 MDB2

BO_ 1187 MDB2_TX_PDO9: 0 MDB2

BO_ 1251 MDB2_TX_PDO10: 0 MDB2

BO_ 1315 MDB2_TX_PDO11: 0 MDB2

BO_ 1379 MDB2_TX_PDO12: 0 MDB2

BO_ 1443 MDB2_SDO_Resp: 8 MDB2
 SG_ MDB2_SDO_RespCode : 12|4@1+ (1,0) [0|0] ""  TelemetryNode
 SG_ MDB2_SDO_ID M : 0|12@1+ (1,0) [0|4095] ""  TelemetryNode

BO_ 1507 MDB2_SDO_Req_Up: 8 TelemetryNode
 SG_ MDB2_SDO_ID M : 0|12@1+ (1,0) [0|4095] ""  MDB2

BO_ 1571 MDB2_SDO_Req_Down: 2 TelemetryNode
 SG_ MDB2_SDO_ID M : 0|12@1+ (1,0) [0|4095] ""  MDB2

BO_ 1827 MDB2_Heartbeat: 1 MDB2
 SG_ MDB2_NodeState : 0|8@1+ (1,0) [0|0] ""  Master,TelemetryNode

BO_ 1891 MDB2_BTL_TX: 8 MDB2

BO_ 1955 MDB2_BTL_RX: 8 TelemetryNode

BO_ 167 MDB3_EMCY: 4 MDB3

BO_ 423 MDB3_TX_PDO1: 0 MDB3

BO_ 487 MDB3_RX_PDO1: 0 Vector__XXX

BO_ 551 MDB3_TX_PDO2: 0 MDB3

BO_ 615 MDB3_RX_PDO2: 0 Vector__XXX

BO_ 679 MDB3_TX_PDO3: 0 MDB3

BO_ 743 MDB3_RX_PDO3: 0 Vector__XXX

BO_ 807 MDB3_TX_PDO4: 0 MDB3

BO_ 871 MDB3_RX_PDO4: 0 Vector__XXX

BO_ 935 MDB3_TX_PDO5: 0 MDB3

BO_ 999 MDB3_TX_PDO6: 0 MDB3

BO_ 1063 MDB3_TX_PDO7: 0 MDB3

BO_ 1127 MDB3_TX_PDO8: 0 MDB3

BO_ 1191 MDB3_TX_PDO9: 0 MDB3

BO_ 1255 MDB3_TX_PDO10: 0 MDB3

BO_ 1319 MDB3_TX_PDO11: 0 MDB3

BO_ 1383 MDB3_TX_PDO12: 0 MDB3

BO_ 1447 MDB3_SDO_Resp: 8 MDB3
 SG_ MDB3_SDO_RespCode : 12|4@1+ (1,0) [0|0] ""  TelemetryNode
 SG_ MDB3_SDO_ID M : 0|12@1+ (1,0) [0|4095] ""  TelemetryNode

BO_ 1511 MDB3_SDO_Req_Up: 8 TelemetryNode
 SG_ MDB3_SDO_ID M : 0|12@1+ (1,0) [0|4095] ""  MDB3

BO_ 1575 MDB3_SDO_Req_Down: 2 TelemetryNode
 SG_ MDB3_SDO_ID M : 0|12@1+ (1,0) [0|4095] ""  MDB3

BO_ 1831 MDB3_Heartbeat: 1 MDB3
 SG_ MDB3_NodeState : 0|8@1+ (1,0) [0|0] ""  Master,TelemetryNode

BO_ 1895 MDB3_BTL_TX: 8 MDB3

BO_ 1959 MDB3_BTL_RX: 8 TelemetryNode

BO_ 168 MDB4_EMCY: 4 MDB4

BO_ 424 MDB4_TX_PDO1: 0 MDB4

BO_ 488 MDB4_RX_PDO1: 0 Vector__XXX

BO_ 552 MDB4_TX_PDO2: 0 MDB4

BO_ 616 MDB4_RX_PDO2: 0 Vector__XXX

BO_ 680 MDB4_TX_PDO3: 0 MDB4

BO_ 744 MDB4_RX_PDO3: 0 Vector__XXX

BO_ 808 MDB4_TX_PDO4: 0 MDB4

BO_ 872 MDB4_RX_PDO4: 0 Vector__XXX

BO_ 936 MDB4_TX_PDO5: 0 MDB4

BO_ 1000 MDB4_TX_PDO6: 0 MDB4

BO_ 1064 MDB4_TX_PDO7: 0 MDB4

BO_ 1128 MDB4_TX_PDO8: 0 MDB4

BO_ 1192 MDB4_TX_PDO9: 0 MDB4

BO_ 1256 MDB4_TX_PDO10: 0 MDB4

BO_ 1320 MDB4_TX_PDO11: 0 MDB4

BO_ 1384 MDB4_TX_PDO12: 0 MDB4

BO_ 1448 MDB4_SDO_Resp: 8 MDB4
 SG_ MDB4_SDO_RespCode : 12|4@1+ (1,0) [0|0] ""  TelemetryNode
 SG_ MDB4_SDO_ID M : 0|12@1+ (1,0) [0|4095] ""  TelemetryNode

BO_ 1512 MDB4_SDO_Req_Up: 8 TelemetryNode
 SG_ MDB4_SDO_ID M : 0|12@1+ (1,0) [0|4095] ""  MDB4

BO_ 1576 MDB4_SDO_Req_Down: 2 TelemetryNode
 SG_ MDB4_SDO_ID M : 0|12@1+ (1,0) [0|4095] ""  MDB4

BO_ 1832 MDB4_Heartbeat: 1 MDB4
 SG_ MDB4_NodeState : 0|8@1+ (1,0) [0|0] ""  Master,TelemetryNode

BO_ 1896 MDB4_BTL_TX: 8 MDB4

BO_ 1960 MDB4_BTL_RX: 8 TelemetryNode

BO_ 169 MDB5_EMCY: 4 MDB5

BO_ 425 MDB5_TX_PDO1: 0 MDB5

BO_ 489 MDB5_RX_PDO1: 0 Vector__XXX

BO_ 553 MDB5_TX_PDO2: 0 MDB5

BO_ 617 MDB5_RX_PDO2: 0 Vector__XXX

BO_ 681 MDB5_TX_PDO3: 0 MDB5

BO_ 745 MDB5_RX_PDO3: 0 Vector__XXX

BO_ 809 MDB5_TX_PDO4: 0 MDB5

BO_ 873 MDB5_RX_PDO4: 0 Vector__XXX

BO_ 937 MDB5_TX_PDO5: 0 MDB5

BO_ 1001 MDB5_TX_PDO6: 0 MDB5

BO_ 1065 MDB5_TX_PDO7: 0 MDB5

BO_ 1129 MDB5_TX_PDO8: 0 MDB5

BO_ 1193 MDB5_TX_PDO9: 0 MDB5

BO_ 1257 MDB5_TX_PDO10: 0 MDB5

BO_ 1321 MDB5_TX_PDO11: 0 MDB5

BO_ 1385 MDB5_TX_PDO12: 0 MDB5

BO_ 1449 MDB5_SDO_Resp: 8 MDB5
 SG_ MDB5_SDO_RespCode : 12|4@1+ (1,0) [0|0] ""  TelemetryNode
 SG_ MDB5_SDO_ID M : 0|12@1+ (1,0) [0|4095] ""  TelemetryNode

BO_ 1513 MDB5_SDO_Req_Up: 8 TelemetryNode
 SG_ MDB5_SDO_ID M : 0|12@1+ (1,0) [0|4095] ""  MDB5

BO_ 1577 MDB5_SDO_Req_Down: 2 TelemetryNode
 SG_ MDB5_SDO_ID M : 0|12@1+ (1,0) [0|4095] ""  MDB5

BO_ 1833 MDB5_Heartbeat: 1 MDB5
 SG_ MDB5_NodeState : 0|8@1+ (1,0) [0|0] ""  Master,TelemetryNode

BO_ 1897 MDB5_BTL_TX: 8 MDB5

BO_ 1961 MDB5_BTL_RX: 8 TelemetryNode

BO_ 177 MDB6_EMCY: 4 MDB6

BO_ 433 MDB6_TX_PDO1: 0 MDB6

BO_ 497 MDB6_RX_PDO1: 0 Vector__XXX

BO_ 561 MDB6_TX_PDO2: 0 MDB6

BO_ 625 MDB6_RX_PDO2: 0 Vector__XXX

BO_ 689 MDB6_TX_PDO3: 0 MDB6

BO_ 753 MDB6_RX_PDO3: 0 Vector__XXX

BO_ 817 MDB6_TX_PDO4: 0 MDB6

BO_ 881 MDB6_RX_PDO4: 0 Vector__XXX

BO_ 945 MDB6_TX_PDO5: 0 MDB6

BO_ 1009 MDB6_TX_PDO6: 0 MDB6

BO_ 1073 MDB6_TX_PDO7: 0 MDB6

BO_ 1137 MDB6_TX_PDO8: 0 MDB6

BO_ 1201 MDB6_TX_PDO9: 0 MDB6

BO_ 1265 MDB6_TX_PDO10: 0 MDB6

BO_ 1329 MDB6_TX_PDO11: 0 MDB6

BO_ 1393 MDB6_TX_PDO12: 0 MDB6

BO_ 1457 MDB6_SDO_Resp: 8 MDB6
 SG_ MDB6_SDO_RespCode : 12|4@1+ (1,0) [0|0] ""  TelemetryNode
 SG_ MDB6_SDO_ID M : 0|12@1+ (1,0) [0|4095] ""  TelemetryNode

BO_ 1521 MDB6_SDO_Req_Up: 8 TelemetryNode
 SG_ MDB6_SDO_ID M : 0|12@1+ (1,0) [0|4095] ""  MDB6

BO_ 1585 MDB6_SDO_Req_Down: 2 TelemetryNode
 SG_ MDB6_SDO_ID M : 0|12@1+ (1,0) [0|4095] ""  MDB6

BO_ 1841 MDB6_Heartbeat: 1 MDB6
 SG_ MDB6_NodeState : 0|8@1+ (1,0) [0|0] ""  Master,TelemetryNode

BO_ 1905 MDB6_BTL_TX: 8 MDB6

BO_ 1969 MDB6_BTL_RX: 8 TelemetryNode

BO_ 178 Track_EMCY: 4 Track

BO_ 434 Track_TX_PDO1: 0 Track

BO_ 498 Track_RX_PDO1: 0 Vector__XXX

BO_ 562 Track_TX_PDO2: 0 Track

BO_ 626 Track_RX_PDO2: 0 Vector__XXX

BO_ 690 Track_TX_PDO3: 0 Track

BO_ 754 Track_RX_PDO3: 0 Vector__XXX

BO_ 818 Track_TX_PDO4: 0 Track

BO_ 882 Track_RX_PDO4: 0 Vector__XXX

BO_ 946 Track_TX_PDO5: 0 Track

BO_ 1010 Track_TX_PDO6: 0 Track

BO_ 1074 Track_TX_PDO7: 0 Track

BO_ 1138 Track_TX_PDO8: 0 Track

BO_ 1202 Track_TX_PDO9: 0 Track

BO_ 1266 Track_TX_PDO10: 0 Track

BO_ 1330 Track_TX_PDO11: 0 Track

BO_ 1394 Track_TX_PDO12: 0 Track

BO_ 1458 Track_SDO_Resp: 8 Track
 SG_ Track_SDO_RespCode : 12|4@1+ (1,0) [0|0] ""  TelemetryNode
 SG_ Track_SDO_ID M : 0|12@1+ (1,0) [0|4095] ""  TelemetryNode

BO_ 1522 Track_SDO_Req_Up: 8 TelemetryNode
 SG_ Track_SDO_ID M : 0|12@1+ (1,0) [0|4095] ""  Track

BO_ 1586 Track_SDO_Req_Down: 2 TelemetryNode
 SG_ Track_SDO_ID M : 0|12@1+ (1,0) [0|4095] ""  Track

BO_ 1842 Track_Heartbeat: 1 Track
 SG_ Track_NodeState : 0|8@1+ (1,0) [0|0] ""  Master,TelemetryNode

BO_ 1906 Track_BTL_TX: 8 Track

BO_ 1970 Track_BTL_RX: 8 TelemetryNode

BO_ 148 CLU_EMCY: 4 CLU

BO_ 404 CLU_TX_PDO1: 0 CLU

BO_ 468 CLU_RX_PDO1: 0 Vector__XXX

BO_ 532 CLU_TX_PDO2: 0 CLU

BO_ 596 CLU_RX_PDO2: 0 Vector__XXX

BO_ 660 CLU_TX_PDO3: 0 CLU

BO_ 724 CLU_RX_PDO3: 0 Vector__XXX

BO_ 788 CLU_TX_PDO4: 0 CLU

BO_ 852 CLU_RX_PDO4: 0 Vector__XXX

BO_ 916 CLU_TX_PDO5: 0 CLU

BO_ 980 CLU_TX_PDO6: 0 CLU

BO_ 1044 CLU_TX_PDO7: 0 CLU

BO_ 1108 CLU_TX_PDO8: 0 CLU

BO_ 1172 CLU_TX_PDO9: 0 CLU

BO_ 1236 CLU_TX_PDO10: 0 CLU

BO_ 1300 CLU_TX_PDO11: 0 CLU

BO_ 1364 CLU_TX_PDO12: 0 CLU

BO_ 1428 CLU_SDO_Resp: 8 CLU
 SG_ CLU_SDO_ID M : 0|12@1+ (1,0) [0|4095] ""  TelemetryNode

BO_ 1492 CLU_SDO_Req_Up: 8 TelemetryNode
 SG_ CLU_SDO_ID M : 0|12@1+ (1,0) [0|4095] ""  CLU

BO_ 1556 CLU_SDO_Req_Down: 2 TelemetryNode
 SG_ CLU_SDO_ID M : 0|12@1+ (1,0) [0|4095] ""  CLU

BO_ 1812 CLU_Heartbeat: 1 CLU
 SG_ CLU_NodeState : 0|8@1+ (1,0) [0|0] ""  Master,TelemetryNode

BO_ 1876 CLU_BTL_TX: 8 CLU

BO_ 1940 CLU_BTL_RX: 8 TelemetryNode

BO_TX_BU_ 260 : MDB3,MDB2,MDB1,MDB6,MDB5,MDB4;
BO_TX_BU_ 257 : MDB3,MDB2,MDB1,MDB6,MDB5,MDB4;
BO_TX_BU_ 256 : MDB3,MDB4,MDB6,MDB1,MDB2;

CM_ BU_ OpticalSensor "Kistler SFP-II optical Sensor.";
CM_ BU_ TelemetryNode "Gateway between Pod and Telemetry
Node-ID 0x22Gateway between Pod and Telemetry
Node-ID 0x22";
CM_ BU_ Master "CANzero NMT Master Node.";
CM_ BU_ SensorF "SensorECU
Node-ID 0x1";
CM_ BU_ SensorR "SensorECUR
Node-ID 0x2";
CM_ BU_ BrakeF "BrakeECU Front
Node-ID 0x11";
CM_ BU_ BrakeR "BrakeECUR
Node-ID 0x12";
CM_ BU_ PDU "PowerD
Node-ID 0x1A";
CM_ BU_ MDB1 "ModularLevitationUnit-1
Node-ID 0x21";
CM_ BU_ MDB2 "ModularLevitationUnit-2
Node-ID 0x23";
CM_ BU_ MDB3 "ModularLevitationUnit-3
Node-ID 0x27";
CM_ BU_ MDB4 "ModularLevitationUnit-4
Node-ID 0x28";
CM_ BU_ MDB5 "ModularLevitationUnit-5
Node-ID 0x29";
CM_ BU_ MDB6 "ModularLevitationUnit-6
Node-ID 0x31";
CM_ BU_ Track "TrackECU
Node-ID 0x32";
CM_ BU_ CLU "central levitation unit
Node-ID 0x14";
CM_ SG_ 274 MDB3_TargetAirGap "as binary IEEE-754
";
CM_ SG_ 295 MDB6_TargetAirGap "as binary IEEE-754
";
CM_ SG_ 297 MDB6_Temperature "as binary IEEE-754";
CM_ SG_ 294 MDB6_TargetAirGap "as binary IEEE-754
";
CM_ SG_ 292 MDB5_Temperature "as binary IEEE-754";
CM_ SG_ 290 MDB5_TargetAirGap "as binary IEEE-754
";
CM_ SG_ 289 MDB5_AirGap "as binary IEEE-754
";
CM_ SG_ 281 MDB4_Temperature "as binary IEEE-754";
CM_ SG_ 279 MDB4_TargetAirGap "as binary IEEE-754
";
CM_ SG_ 278 MDB4_AirGap "as binary IEEE-754
";
CM_ SG_ 276 MDB3_Temperature "as binary IEEE-754";
CM_ SG_ 273 MDB3_AirGap "as binary IEEE-754
";
CM_ SG_ 265 MDB2_Temperature "as binary IEEE-754";
CM_ SG_ 263 MDB2_TargetAirGap "as binary IEEE-754
";
CM_ SG_ 262 MDB2_AirGap "as binary IEEE-754
";
CM_ SG_ 258 MDB1_TargetAirGap "as binary IEEE-754
";
CM_ SG_ 260 MDB1_Temperature "as binary IEEE-754";
CM_ SG_ 257 MDB1_AirGap "as binary IEEE-754
";
CM_ BO_ 2684354555 "longitudinal and transverse velocity, angle between them";
CM_ SG_ 2684354555 OpticalSensor_TX_Angle "Angle between longitudianl and transverse direction.";
CM_ SG_ 2684354555 OpticalSensor_TX_VelTrans "Velocity in transverse direction.";
CM_ SG_ 2684354555 OpticalSensor_TX_VelLong "Velocity in longitudinal direction.";
CM_ BO_ 2684354554 "Timestamp, Veocity, Distance";
CM_ SG_ 2684354554 OpticalSensor_TX_Distance "Traveled distance";
CM_ SG_ 2684354554 OpticalSensor_TX_Vel "Absolute velocity";
CM_ BO_ 2684354556 "Timestamp, Veocity, Distance";
CM_ SG_ 2684354556 OpticalSensor_TX_Temp "Temperature of the sensor";
CM_ SG_ 2684354556 OpticalSensor_TX_SerialNo "Serialnumber of the sensor";
CM_ BO_ 2 "CANzero NMT message sent by NMT master.";
CM_ SG_ 2 CANzero_NMT_Node "CANzero NMT Node-ID of master request.";
CM_ SG_ 2 CANzero_NMT_State "CANzero NMT State Request by master.";
CM_ BO_ 122 "CANzero Sync message. Not used yet, just a placeholder for future versions.";
CM_ BO_ 123 "CANzero Timestamp message. Not used yet, just a placeholder for future versions.";
CM_ BO_ 129 "Emergency message of node SensorF with Node-ID 0x1";
CM_ BO_ 385 "Transmit PDO 1 of node SensorF with Node-ID 0x1";
CM_ SG_ 385 SensorF_TX_PodState "PodState by State Machine.";
CM_ BO_ 449 "Receive PDO 1 of node SensorF with Node-ID 0x1";
CM_ BO_ 513 "Data from Encoder front (PDO10)";
CM_ BO_ 577 "Receive PDO 2 of node SensorF with Node-ID 0x1.";
CM_ BO_ 641 "Transmit PDO 3 of node SensorF with Node-ID 0x1";
CM_ BO_ 705 "Receive PDO 3 of node SensorF with Node-ID 0x1.";
CM_ BO_ 769 "Transmit PDO 4 of node SensorF with Node-ID 0x1";
CM_ BO_ 833 "Receive PDO 4 of node SensorF with Node-ID 0x1.";
CM_ BO_ 897 "Transmit PDO 5 of node SensorF with Node-ID 0x1";
CM_ BO_ 961 "Transmit PDO 6 of node SensorF with Node-ID 0x1";
CM_ BO_ 1025 "Transmit PDO 7 of node SensorF with Node-ID 0x1";
CM_ SG_ 1025 SensorF_GyroFront_X "Slope of front IMU in X direction.";
CM_ SG_ 1025 SensorF_Vel_EncoderFront "Velocity of Wheel Encoder front.";
CM_ SG_ 1025 SensorF_Pos_EncoderFront "Position of Wheel Encoder front.";
CM_ BO_ 1089 "Transmit PDO 8 of node SensorF with Node-ID 0x1";
CM_ BO_ 1153 "Transmit PDO 9 of node SensorF with Node-ID 0x1";
CM_ BO_ 1217 "Transmit Acc_X, Acc_Y, Acc_Z and Gyro_Z of front IMU of node SensorF.";
CM_ SG_ 1217 SensorF_GyroFront_Z "Slope of front IMU in Z direction.";
CM_ SG_ 1217 SensorF_AccFront_Z "Acceleration of front IMU in Z direction.";
CM_ SG_ 1217 SensorF_AccFront_Y "Acceleration of front IMU in Y direction.";
CM_ SG_ 1217 SensorF_AccFront_X "Acceleration of front IMU in X direction.";
CM_ BO_ 1281 "SensorF with Node-ID 0x1 (PDO11).";
CM_ BO_ 1345 "Transmit PDO 12 of node SensorF with Node-ID 0x1.";
CM_ BO_ 1409 "DO NOT CHANGE ANYTHING HERE!
SDO Response of node SensorF with Node-ID 0x1";
CM_ SG_ 1409 SensorF_SDO_RespCode "Response code of SDO access.";
CM_ SG_ 1409 SensorF_SDO_ID "Specifies SDO-ID of SensorF";
CM_ BO_ 1473 "DO NOT CHANGE ANYTHING HERE!
SDO Request Upload to node SensorF with Node-ID 0x1";
CM_ SG_ 1473 SensorF_SDO_ID "Specifies SDO-ID of SensorF";
CM_ BO_ 1537 "DO NOT CHANGE ANYTHING HERE!
SDO Request Download from node SensorF with Node-ID 0x1";
CM_ SG_ 1537 SensorF_SDO_ID "Specifies SDO-ID of SensorF";
CM_ BO_ 1793 "Heartbeat of node SensorF with Node-ID 0x1";
CM_ SG_ 1793 SensorF_NodeState "Heartbeat status of node SensorF";
CM_ BO_ 1857 "Bootloader transmit from node SensorF with Node-ID 0x1";
CM_ BO_ 1921 "Bootloader receive by node SensorF with Node-ID 0x1";
CM_ BO_ 130 "Emergency message of node SensorR with Node-ID 0x2";
CM_ BO_ 386 "Transmit PDO 1 of node SensorR with Node-ID 0x2. Data of front IMU.";
CM_ SG_ 386 SensorR_TX_GyroFront_Z "Slope of front IMU in Z direction.";
CM_ SG_ 386 SensorR_TX_AccFront_Z "Acceleration of front IMU in Z direction.";
CM_ SG_ 386 SensorR_TX_AccFront_Y "Acceleration of front IMU in Y direction.";
CM_ SG_ 386 SensorR_TX_AccFront_X "Acceleration of front IMU in X direction.";
CM_ BO_ 514 "Transmit PDO 2 of node SensorR with Node-ID 0x2. RunState, Enabled, ErrorFlag, TrajectorySet";
CM_ SG_ 514 SensorR_TX_ErrorFlag "Error status of SensorR.";
CM_ SG_ 514 SensorR_TX_Enabled "Enable status of SensorR.";
CM_ SG_ 514 SensorR_TX_TrajectorySet "Flag for trajectorySet";
CM_ SG_ 514 SensorR_TX_RunState "State of run of SensorR.";
CM_ BO_ 578 "Receive PDO 2 of node SensorR with Node-ID 0x2.";
CM_ BO_ 642 "Transmit PDO 3 of node SensorR with Node-ID 0x2. Filtered data after StateEstimation";
CM_ SG_ 642 SensorR_TX_Pos "Filtered position by StateEstimation.";
CM_ SG_ 642 SensorR_TX_Vel "Filtered velocity by StateEstimation.";
CM_ SG_ 642 SensorR_TX_Acc "Filtered acceleration by StateEstimation.";
CM_ BO_ 706 "Receive PDO 3 of node SensorR with Node-ID 0x2";
CM_ SG_ 706 SensorR_RX_ErrorReset "Error reset signal for SensorR.";
CM_ SG_ 706 SensorR_RX_Enable "Enable signal for SensorR.";
CM_ SG_ 706 SensorR_RX_LaunchComm "Launch Command of SensorR.";
CM_ BO_ 770 "Transmit PDO 4 of node SensorR with Node-ID 0x2. Velocity of EncoderFront, rear and optical, Stripes";
CM_ SG_ 770 SensorR_TX_Vel_Optical "Velocity of optical Sensor.";
CM_ SG_ 770 SensorR_TX_Vel_EncoderRear "Velocity of Wheel Encoder rear.";
CM_ SG_ 770 SensorR_TX_Vel_EncoderFront "Velocity of Wheel Encoder front.";
CM_ BO_ 834 "Receive PDO 4 of node SensorR with Node-ID 0x2.";
CM_ BO_ 898 "Transmit PDO 5 of node SensorR with Node-ID 0x2. Gyroscope data of IMU front and rear in X and Y direction.";
CM_ SG_ 898 SensorR_TX_GyroRear_Y "Slope of rear IMU in Y direction.";
CM_ SG_ 898 SensorR_TX_GyroRear_X "Slope of rear IMU in X direction.";
CM_ SG_ 898 SensorR_TX_GyroFront_Y "Slope of front IMU in Y direction.";
CM_ SG_ 898 SensorR_TX_GyroFront_X "Slope of front IMU in X direction.";
CM_ BO_ 962 "Transmit PDO 6 of node SensorR with Node-ID 0x2";
CM_ BO_ 1026 "Transmit PDO 7 of node SensorR with Node-ID 0x2. Gap Height of left and right sensor.";
CM_ SG_ 1026 SensorR_TX_GapHeight_Right "Gap height of LIM right.";
CM_ SG_ 1026 SensorR_TX_GapHeight_Left "Gap height of LIM left.";
CM_ BO_ 1090 "Transmit PDO 8 of node SensorR with Node-ID 0x2";
CM_ BO_ 1154 "Transmit PDO 9 of node SensorR with Node-ID 0x2";
CM_ BO_ 1218 "Transmit PDO 10 of node SensorR with Node-ID 0x2. Send acceleration of IMU Rear.";
CM_ SG_ 1218 SensorR_TX_GyroRear_Z "Slope of rear IMU in Z direction.";
CM_ SG_ 1218 SensorR_TX_AccRear_Z "Acceleration of rear IMU in Z direction.";
CM_ SG_ 1218 SensorR_TX_AccRear_Y "Acceleration of rear IMU in Y direction.";
CM_ SG_ 1218 SensorR_TX_AccRear_X "Acceleration of rear IMU in X direction.";
CM_ BO_ 1282 "Transmit PDO 11 of node SensorR with Node-ID 0x2. Send position data of Encoder front, rear and optical and Stripes.";
CM_ SG_ 1282 SensorR_TX_StripeCounter_Right "Counting reflectors on the right site.";
CM_ SG_ 1282 SensorR_TX_StripeCounter_Left "Counting reflectors on the left site.";
CM_ SG_ 1282 SensorR_TX_Pos_Optical "Position of optical Sensor.";
CM_ SG_ 1282 SensorR_TX_Pos_EncoderRear "Position of Wheel Encoder rear.";
CM_ SG_ 1282 SensorR_TX_Pos_EncoderFront "Position of Wheel Encoder front.";
CM_ BO_ 1346 "Transmit PDO 12 of node SensorR with Node-ID 0x2.";
CM_ BO_ 1410 "DO NOT CHANGE ANYTHING HERE!
SDO Response of node SensorR with Node-ID 0x2";
CM_ SG_ 1410 SensorR_SDO_RespCode "Response code of SDO access.";
CM_ SG_ 1410 SensorR_SDO_ID "Specifies SDO-ID of SensorR";
CM_ BO_ 1474 "DO NOT CHANGE ANYTHING HERE!
SDO Request Upload to node SensorR with Node-ID 0x2";
CM_ SG_ 1474 SensorR_SDO_ID "Specifies SDO-ID of SensorR";
CM_ BO_ 1538 "DO NOT CHANGE ANYTHING HERE!
SDO Request Download from node SensorR with Node-ID 0x2";
CM_ SG_ 1538 SensorR_SDO_ID "Specifies SDO-ID of SensorR";
CM_ BO_ 1794 "Heartbeat of node SensorR with Node-ID 0x2";
CM_ SG_ 1794 SensorR_NodeState "Heartbeat status of node SensorR";
CM_ BO_ 1858 "Bootloader transmit from node SensorR with Node-ID 0x2";
CM_ BO_ 1922 "Bootloader receive by node SensorR with Node-ID 0x2";
CM_ BO_ 145 "Emergency message of node BrakeF with Node-ID 0x11";
CM_ BO_ 401 "Transmit PDO 1 of node BrakeF with Node-ID 0x11";
CM_ SG_ 401 BrakeF_TX_SDC_Input "Sends the current value of the SDC received by BrakeF.
";
CM_ SG_ 401 BrakeF_TX_ErrorFlag "Error status of BrakeF.";
CM_ SG_ 401 BrakeF_TX_Enabled "Enable status of BrakeF.";
CM_ SG_ 401 BrakeF_TX_Status "Status signal of BrakeF.";
CM_ BO_ 465 "Receive PDO 1 of node BrakeF with Node-ID 0x11";
CM_ SG_ 465 BrakeF_RX_Engage "Engage signal for BrakeF.";
CM_ SG_ 465 BrakeF_RX_Enable "Enable signal for BrakeF.";
CM_ SG_ 465 BrakeF_RX_ErrorReset "Error reset signal for BrakeF.";
CM_ BO_ 529 "Transmit PDO 2 of node BrakeF with Node-ID 0x11";
CM_ BO_ 593 "Receive PDO 2 of node BrakeF with Node-ID 0x11";
CM_ BO_ 657 "Transmit PDO 3 of node BrakeF with Node-ID 0x11";
CM_ BO_ 721 "Receive PDO 3 of node BrakeF with Node-ID 0x11";
CM_ BO_ 785 "Transmit PDO 4 of node BrakeF with Node-ID 0x11";
CM_ BO_ 849 "Receive PDO 4 of node BrakeF with Node-ID 0x11";
CM_ BO_ 913 "Transmit PDO 5 of node BrakeF with Node-ID 0x11";
CM_ BO_ 977 "Transmit PDO 6 of node BrakeF with Node-ID 0x11";
CM_ BO_ 1105 "Transmit PDO 8 of node BrakeF with Node-ID 0x11";
CM_ BO_ 1169 "Transmit PDO 9 of node BrakeF with Node-ID 0x11";
CM_ BO_ 1233 "Transmit PDO 10 of node BrakeF with Node-ID 0x11";
CM_ BO_ 1297 "Transmit PDO 11 of node BrakeF with Node-ID 0x11";
CM_ BO_ 1361 "Transmit PDO 12 of node BrakeF with Node-ID 0x11";
CM_ BO_ 1425 "DO NOT CHANGE ANYTHING HERE!
SDO Response of node BrakeF with Node-ID 0x11";
CM_ SG_ 1425 BrakeF_SDO_RespCode "Response code of SDO access.";
CM_ SG_ 1425 BrakeF_SDO_ID "Specifies SDO-ID of BrakeF";
CM_ BO_ 1489 "DO NOT CHANGE ANYTHING HERE!
SDO Request Upload to node BrakeF with Node-ID 0x11";
CM_ SG_ 1489 BrakeF_SDO_ID "Specifies SDO-ID of BrakeF";
CM_ BO_ 1553 "DO NOT CHANGE ANYTHING HERE!
SDO Request Download from node BrakeF with Node-ID 0x11";
CM_ SG_ 1553 BrakeF_SDO_ID "Specifies SDO-ID of BrakeF";
CM_ BO_ 1809 "Heartbeat of node BrakeF with Node-ID 0x11";
CM_ SG_ 1809 BrakeF_NodeState "Heartbeat status of node BrakeF";
CM_ BO_ 1873 "Bootloader transmit from node BrakeF with Node-ID 0x11";
CM_ BO_ 1937 "Bootloader receive by node BrakeF with Node-ID 0x11";
CM_ BO_ 146 "Emergency message of node BrakeR with Node-ID 0x12";
CM_ BO_ 402 "Transmit PDO 1 of node BrakeR with Node-ID 0x12";
CM_ SG_ 402 BrakeR_TX_SDC_Input "Sends the current value of the SDC received by BrakeR.
";
CM_ SG_ 402 BrakeR_TX_ErrorFlag "Error status of BrakeR.";
CM_ SG_ 402 BrakeR_TX_Enabled "Enable status of BrakeR.";
CM_ SG_ 402 BrakeR_TX_Status "Status signal of BrakeR.";
CM_ BO_ 466 "Receive PDO 1 of node BrakeR with Node-ID 0x12";
CM_ SG_ 466 BrakeR_RX_Engage "Engage signal for BrakeR.";
CM_ SG_ 466 BrakeR_RX_Enable "Enable signal for BrakeR.";
CM_ SG_ 466 BrakeR_RX_ErrorReset "Error reset signal for BrakeR.";
CM_ BO_ 530 "Transmit PDO 2 of node BrakeR with Node-ID 0x12";
CM_ BO_ 594 "Receive PDO 2 of node BrakeR with Node-ID 0x12";
CM_ BO_ 658 "Transmit PDO 3 of node BrakeR with Node-ID 0x12";
CM_ BO_ 722 "Receive PDO 3 of node BrakeR with Node-ID 0x12";
CM_ BO_ 786 "Transmit PDO 4 of node BrakeR with Node-ID 0x12";
CM_ BO_ 850 "Receive PDO 4 of node BrakeR with Node-ID 0x12";
CM_ BO_ 914 "Transmit PDO 5 of node BrakeR with Node-ID 0x12";
CM_ BO_ 978 "Transmit PDO 6 of node BrakeR with Node-ID 0x12";
CM_ BO_ 1042 "Transmit PDO 7 of node BrakeR with Node-ID 0x12";
CM_ BO_ 1106 "Transmit PDO 8 of node BrakeR with Node-ID 0x12";
CM_ BO_ 1170 "Transmit PDO 9 of node BrakeR with Node-ID 0x12";
CM_ BO_ 1234 "Transmit PDO 10 of node BrakeR with Node-ID 0x12";
CM_ BO_ 1298 "Transmit PDO 11 of node BrakeR with Node-ID 0x12";
CM_ BO_ 1362 "Transmit PDO 12 of node BrakeR with Node-ID 0x12";
CM_ BO_ 1426 "DO NOT CHANGE ANYTHING HERE!
SDO Response of node BrakeR with Node-ID 0x12";
CM_ SG_ 1426 BrakeR_SDO_RespCode "Response code of SDO access.";
CM_ SG_ 1426 BrakeR_SDO_ID "Specifies SDO-ID of BrakeR";
CM_ BO_ 1490 "DO NOT CHANGE ANYTHING HERE!
SDO Request Upload to node BrakeR with Node-ID 0x12";
CM_ SG_ 1490 BrakeR_SDO_ID "Specifies SDO-ID of BrakeR";
CM_ BO_ 1554 "DO NOT CHANGE ANYTHING HERE!
SDO Request Download from node BrakeR with Node-ID 0x12";
CM_ SG_ 1554 BrakeR_SDO_ID "Specifies SDO-ID of BrakeR";
CM_ BO_ 1810 "Heartbeat of node BrakeR with Node-ID 0x12";
CM_ SG_ 1810 BrakeR_NodeState "Heartbeat status of node BrakeR";
CM_ BO_ 1874 "Bootloader transmit from node BrakeR with Node-ID 0x12";
CM_ BO_ 1938 "Bootloader receive by node BrakeR with Node-ID 0x12";
CM_ BO_ 154 "Emergency message of node PDU with Node-ID 0x1A";
CM_ BO_ 410 "Transmit PDO 1 of node PDU with Node-ID 0x1A";
CM_ SG_ 410 PDU_TX_PEHWEnabled "PE Hardware Enable status signal of PDU.";
CM_ SG_ 410 PDU_TX_ErrorFlag "Error status of PDU.";
CM_ SG_ 410 PDU_TX_Enabled "Enable status of PDU.";
CM_ BO_ 474 "Control message of the PDU sent by the State Machine.";
CM_ SG_ 474 PDU_RX_PEHWEnable "PE Hardware Enable signal of PDU.";
CM_ SG_ 474 PDU_RX_ErrorReset "Error reset signal for PDU.";
CM_ SG_ 474 PDU_RX_Enable "Enable signal for PDU.";
CM_ BO_ 538 "Transmit PDO 2 of node PDU with Node-ID 0x1A";
CM_ BO_ 602 "Dutycycle for the channels of the PDU that support PWM.";
CM_ BO_ 666 "Transmit PDO 3 of node PDU with Node-ID 0x1A";
CM_ BO_ 730 "Receive PDO 3 of node PDU with Node-ID 0x1A";
CM_ BO_ 794 "Transmit PDO 4 of node PDU with Node-ID 0x1A";
CM_ BO_ 858 "Receive PDO 4 of node PDU with Node-ID 0x1A";
CM_ BO_ 922 "Transmit PDO 5 of node PDU with Node-ID 0x1A";
CM_ BO_ 986 "Transmit PDO 6 of node PDU with Node-ID 0x1A";
CM_ BO_ 1050 "Transmit PDO 7 of node PDU with Node-ID 0x1A";
CM_ BO_ 1114 "Transmit PDO 8 of node PDU with Node-ID 0x1A";
CM_ BO_ 1178 "Transmit PDO 9 of node PDU with Node-ID 0x1A";
CM_ BO_ 1242 "Transmit PDO 10 of node PDU with Node-ID 0x1A";
CM_ BO_ 1306 "Transmit PDO 11 of node PDU with Node-ID 0x1A";
CM_ BO_ 1370 "Transmit PDO 12 of node PDU with Node-ID 0x1A";
CM_ BO_ 1434 "DO NOT CHANGE ANYTHING HERE!
SDO Response of node PDU with Node-ID 0x1A";
CM_ SG_ 1434 PDU_SDO_RespCode "Response code of SDO access.";
CM_ SG_ 1434 PDU_SDO_ID "Specifies SDO-ID of PDU";
CM_ BO_ 1498 "DO NOT CHANGE ANYTHING HERE!
SDO Request Upload to node PDU with Node-ID 0x1A";
CM_ SG_ 1498 PDU_SDO_ID "Specifies SDO-ID of PDU";
CM_ BO_ 1562 "DO NOT CHANGE ANYTHING HERE!
SDO Request Download from node PDU with Node-ID 0x1A";
CM_ SG_ 1562 PDU_SDO_ID "Specifies SDO-ID of PDU";
CM_ BO_ 1818 "Heartbeat of node PDU with Node-ID 0x1A";
CM_ SG_ 1818 PDU_NodeState "Heartbeat status of node PDU";
CM_ BO_ 1882 "Bootloader transmit from node PDU with Node-ID 0x1A";
CM_ BO_ 1946 "Bootloader receive by node PDU with Node-ID 0x1A";
CM_ BO_ 162 "Emergency message of node TelemetryNode with Node-ID 0x22";
CM_ BO_ 418 "Transmit PDO 1 of node TelemetryNode with Node-ID 0x22";
CM_ BO_ 482 "Receive PDO 1 of node TelemetryNode with Node-ID 0x22";
CM_ BO_ 546 "Transmit PDO 2 of node TelemetryNode with Node-ID 0x22";
CM_ BO_ 610 "Receive PDO 2 of node TelemetryNode with Node-ID 0x22";
CM_ BO_ 674 "Transmit PDO 3 of node TelemetryNode with Node-ID 0x22";
CM_ BO_ 738 "Receive PDO 3 of node TelemetryNode with Node-ID 0x22";
CM_ BO_ 802 "Transmit PDO 4 of node TelemetryNode with Node-ID 0x22";
CM_ BO_ 866 "Receive PDO 4 of node TelemetryNode with Node-ID 0x22";
CM_ BO_ 930 "Transmit PDO 5 of node TelemetryNode with Node-ID 0x22";
CM_ BO_ 994 "Transmit PDO 6 of node TelemetryNode with Node-ID 0x22";
CM_ BO_ 1058 "Transmit PDO 7 of node TelemetryNode with Node-ID 0x22";
CM_ BO_ 1122 "Transmit PDO 8 of node TelemetryNode with Node-ID 0x22";
CM_ BO_ 1186 "Transmit PDO 9 of node TelemetryNode with Node-ID 0x22";
CM_ BO_ 1250 "Transmit PDO 10 of node TelemetryNode with Node-ID 0x22";
CM_ BO_ 1314 "Transmit PDO 11 of node TelemetryNode with Node-ID 0x22";
CM_ BO_ 1378 "Transmit PDO 12 of node TelemetryNode with Node-ID 0x22";
CM_ BO_ 1442 "DO NOT CHANGE ANYTHING HERE!
SDO Response of node TelemetryNode with Node-ID 0x22";
CM_ SG_ 1442 TelemetryNode_SDO_RespCode "Response code of SDO access.";
CM_ SG_ 1442 TelemetryNode_SDO_ID "Specifies SDO-ID of TelemetryNode";
CM_ BO_ 1506 "DO NOT CHANGE ANYTHING HERE!
SDO Request Upload to node TelemetryNode with Node-ID 0x22";
CM_ SG_ 1506 TelemetryNode_SDO_ID "Specifies SDO-ID of TelemetryNode";
CM_ BO_ 1570 "DO NOT CHANGE ANYTHING HERE!
SDO Request Download from node TelemetryNode with Node-ID 0x22";
CM_ SG_ 1570 TelemetryNode_SDO_ID "Specifies SDO-ID of TelemetryNode";
CM_ BO_ 1826 "Heartbeat of node TelemetryNode with Node-ID 0x22";
CM_ SG_ 1826 TelemetryNode_NodeState "Heartbeat status of node TelemetryNode";
CM_ BO_ 1890 "Bootloader transmit from node TelemetryNode with Node-ID 0x22";
CM_ BO_ 1954 "Bootloader receive by node TelemetryNode with Node-ID 0x22";
CM_ BO_ 161 "Emergency message of node MDB1 with Node-ID 0x21";
CM_ BO_ 417 "Transmit PDO 1 of node MDB1 with Node-ID 0x21";
CM_ BO_ 481 "Receive PDO 1 of node MDB1 with Node-ID 0x21";
CM_ BO_ 545 "Transmit PDO 2 of node MDB1 with Node-ID 0x21";
CM_ BO_ 609 "Receive PDO 2 of node MDB1 with Node-ID 0x21";
CM_ BO_ 673 "Transmit PDO 3 of node MDB1 with Node-ID 0x21";
CM_ BO_ 737 "Receive PDO 3 of node MDB1 with Node-ID 0x21";
CM_ BO_ 801 "Transmit PDO 4 of node MDB1 with Node-ID 0x21";
CM_ BO_ 865 "Receive PDO 4 of node MDB1 with Node-ID 0x21";
CM_ BO_ 929 "Transmit PDO 5 of node MDB1 with Node-ID 0x21";
CM_ BO_ 993 "Transmit PDO 6 of node MDB1 with Node-ID 0x21";
CM_ BO_ 1057 "Transmit PDO 7 of node MDB1 with Node-ID 0x21";
CM_ BO_ 1121 "Transmit PDO 8 of node MDB1 with Node-ID 0x21";
CM_ BO_ 1185 "Transmit PDO 9 of node MDB1 with Node-ID 0x21";
CM_ BO_ 1249 "Transmit PDO 10 of node MDB1 with Node-ID 0x21";
CM_ BO_ 1313 "Transmit PDO 11 of node MDB1 with Node-ID 0x21";
CM_ BO_ 1377 "Transmit PDO 12 of node MDB1 with Node-ID 0x21";
CM_ BO_ 1441 "DO NOT CHANGE ANYTHING HERE!
SDO Response of node MDB1 with Node-ID 0x21";
CM_ SG_ 1441 MDB1_SDO_RespCode "Response code of SDO access.";
CM_ SG_ 1441 MDB1_SDO_ID "Specifies SDO-ID of MDB1";
CM_ BO_ 1505 "DO NOT CHANGE ANYTHING HERE!
SDO Request Upload to node MDB1 with Node-ID 0x21";
CM_ SG_ 1505 MDB1_SDO_ID "Specifies SDO-ID of MDB1";
CM_ BO_ 1569 "DO NOT CHANGE ANYTHING HERE!
SDO Request Download from node MDB1 with Node-ID 0x21";
CM_ SG_ 1569 MDB1_SDO_ID "Specifies SDO-ID of MDB1";
CM_ BO_ 1825 "Heartbeat of node MDB1 with Node-ID 0x21";
CM_ SG_ 1825 MDB1_NodeState "Heartbeat status of node MDB1";
CM_ BO_ 1889 "Bootloader transmit from node MDB1 with Node-ID 0x21";
CM_ BO_ 1953 "Bootloader receive by node MDB1 with Node-ID 0x21";
CM_ BO_ 163 "Emergency message of node MDB2 with Node-ID 0x23";
CM_ BO_ 419 "Transmit PDO 1 of node MDB2 with Node-ID 0x23";
CM_ BO_ 483 "Receive PDO 1 of node MDB2 with Node-ID 0x23";
CM_ BO_ 547 "Transmit PDO 2 of node MDB2 with Node-ID 0x23";
CM_ BO_ 611 "Receive PDO 2 of node MDB2 with Node-ID 0x23";
CM_ BO_ 675 "Transmit PDO 3 of node MDB2 with Node-ID 0x23";
CM_ BO_ 739 "Receive PDO 3 of node MDB2 with Node-ID 0x23";
CM_ BO_ 803 "Transmit PDO 4 of node MDB2 with Node-ID 0x23";
CM_ BO_ 867 "Receive PDO 4 of node MDB2 with Node-ID 0x23";
CM_ BO_ 931 "Transmit PDO 5 of node MDB2 with Node-ID 0x23";
CM_ BO_ 995 "Transmit PDO 6 of node MDB2 with Node-ID 0x23";
CM_ BO_ 1059 "Transmit PDO 7 of node MDB2 with Node-ID 0x23";
CM_ BO_ 1123 "Transmit PDO 8 of node MDB2 with Node-ID 0x23";
CM_ BO_ 1187 "Transmit PDO 9 of node MDB2 with Node-ID 0x23";
CM_ BO_ 1251 "Transmit PDO 10 of node MDB2 with Node-ID 0x23";
CM_ BO_ 1315 "Transmit PDO 11 of node MDB2 with Node-ID 0x23";
CM_ BO_ 1379 "Transmit PDO 12 of node MDB2 with Node-ID 0x23";
CM_ BO_ 1443 "DO NOT CHANGE ANYTHING HERE!
SDO Response of node MDB2 with Node-ID 0x23";
CM_ SG_ 1443 MDB2_SDO_RespCode "Response code of SDO access.";
CM_ SG_ 1443 MDB2_SDO_ID "Specifies SDO-ID of MDB2";
CM_ BO_ 1507 "DO NOT CHANGE ANYTHING HERE!
SDO Request Upload to node MDB2 with Node-ID 0x23";
CM_ SG_ 1507 MDB2_SDO_ID "Specifies SDO-ID of MDB2";
CM_ BO_ 1571 "DO NOT CHANGE ANYTHING HERE!
SDO Request Download from node MDB2 with Node-ID 0x23";
CM_ SG_ 1571 MDB2_SDO_ID "Specifies SDO-ID of MDB2";
CM_ BO_ 1827 "Heartbeat of node MDB2 with Node-ID 0x23";
CM_ SG_ 1827 MDB2_NodeState "Heartbeat status of node MDB2";
CM_ BO_ 1891 "Bootloader transmit from node MDB2 with Node-ID 0x23";
CM_ BO_ 1955 "Bootloader receive by node MDB2 with Node-ID 0x23";
CM_ BO_ 167 "Emergency message of node MDB3 with Node-ID 0x27";
CM_ BO_ 423 "Transmit PDO 1 of node MDB3 with Node-ID 0x27";
CM_ BO_ 487 "Receive PDO 1 of node MDB3 with Node-ID 0x27";
CM_ BO_ 551 "Transmit PDO 2 of node MDB3 with Node-ID 0x27";
CM_ BO_ 615 "Receive PDO 2 of node MDB3 with Node-ID 0x27";
CM_ BO_ 679 "Transmit PDO 3 of node MDB3 with Node-ID 0x27";
CM_ BO_ 743 "Receive PDO 3 of node MDB3 with Node-ID 0x27";
CM_ BO_ 807 "Transmit PDO 4 of node MDB3 with Node-ID 0x27";
CM_ BO_ 871 "Receive PDO 4 of node MDB3 with Node-ID 0x27";
CM_ BO_ 935 "Transmit PDO 5 of node MDB3 with Node-ID 0x27";
CM_ BO_ 999 "Transmit PDO 6 of node MDB3 with Node-ID 0x27";
CM_ BO_ 1063 "Transmit PDO 7 of node MDB3 with Node-ID 0x27";
CM_ BO_ 1127 "Transmit PDO 8 of node MDB3 with Node-ID 0x27";
CM_ BO_ 1191 "Transmit PDO 9 of node MDB3 with Node-ID 0x27";
CM_ BO_ 1255 "Transmit PDO 10 of node MDB3 with Node-ID 0x27";
CM_ BO_ 1319 "Transmit PDO 11 of node MDB3 with Node-ID 0x27";
CM_ BO_ 1383 "Transmit PDO 12 of node MDB3 with Node-ID 0x27";
CM_ BO_ 1447 "DO NOT CHANGE ANYTHING HERE!
SDO Response of node MDB3 with Node-ID 0x27";
CM_ SG_ 1447 MDB3_SDO_RespCode "Response code of SDO access.";
CM_ SG_ 1447 MDB3_SDO_ID "Specifies SDO-ID of MDB3";
CM_ BO_ 1511 "DO NOT CHANGE ANYTHING HERE!
SDO Request Upload to node MDB3 with Node-ID 0x27";
CM_ SG_ 1511 MDB3_SDO_ID "Specifies SDO-ID of MDB3";
CM_ BO_ 1575 "DO NOT CHANGE ANYTHING HERE!
SDO Request Download from node MDB3 with Node-ID 0x27";
CM_ SG_ 1575 MDB3_SDO_ID "Specifies SDO-ID of MDB3";
CM_ BO_ 1831 "Heartbeat of node MDB3 with Node-ID 0x27";
CM_ SG_ 1831 MDB3_NodeState "Heartbeat status of node MDB3";
CM_ BO_ 1895 "Bootloader transmit from node MDB3 with Node-ID 0x27";
CM_ BO_ 1959 "Bootloader receive by node MDB3 with Node-ID 0x27";
CM_ BO_ 168 "Emergency message of node MDB4 with Node-ID 0x28";
CM_ BO_ 424 "Transmit PDO 1 of node MDB4 with Node-ID 0x28";
CM_ BO_ 488 "Receive PDO 1 of node MDB4 with Node-ID 0x28";
CM_ BO_ 552 "Transmit PDO 2 of node MDB4 with Node-ID 0x28";
CM_ BO_ 616 "Receive PDO 2 of node MDB4 with Node-ID 0x28";
CM_ BO_ 680 "Transmit PDO 3 of node MDB4 with Node-ID 0x28";
CM_ BO_ 744 "Receive PDO 3 of node MDB4 with Node-ID 0x28";
CM_ BO_ 808 "Transmit PDO 4 of node MDB4 with Node-ID 0x28";
CM_ BO_ 872 "Receive PDO 4 of node MDB4 with Node-ID 0x28";
CM_ BO_ 936 "Transmit PDO 5 of node MDB4 with Node-ID 0x28";
CM_ BO_ 1000 "Transmit PDO 6 of node MDB4 with Node-ID 0x28";
CM_ BO_ 1064 "Transmit PDO 7 of node MDB4 with Node-ID 0x28";
CM_ BO_ 1128 "Transmit PDO 8 of node MDB4 with Node-ID 0x28";
CM_ BO_ 1192 "Transmit PDO 9 of node MDB4 with Node-ID 0x28";
CM_ BO_ 1256 "Transmit PDO 10 of node MDB4 with Node-ID 0x28";
CM_ BO_ 1320 "Transmit PDO 11 of node MDB4 with Node-ID 0x28";
CM_ BO_ 1384 "Transmit PDO 12 of node MDB4 with Node-ID 0x28";
CM_ BO_ 1448 "DO NOT CHANGE ANYTHING HERE!
SDO Response of node MDB4 with Node-ID 0x28";
CM_ SG_ 1448 MDB4_SDO_RespCode "Response code of SDO access.";
CM_ SG_ 1448 MDB4_SDO_ID "Specifies SDO-ID of MDB4";
CM_ BO_ 1512 "DO NOT CHANGE ANYTHING HERE!
SDO Request Upload to node MDB4 with Node-ID 0x28";
CM_ SG_ 1512 MDB4_SDO_ID "Specifies SDO-ID of MDB4";
CM_ BO_ 1576 "DO NOT CHANGE ANYTHING HERE!
SDO Request Download from node MDB4 with Node-ID 0x28";
CM_ SG_ 1576 MDB4_SDO_ID "Specifies SDO-ID of MDB4";
CM_ BO_ 1832 "Heartbeat of node MDB4 with Node-ID 0x28";
CM_ SG_ 1832 MDB4_NodeState "Heartbeat status of node MDB4";
CM_ BO_ 1896 "Bootloader transmit from node MDB4 with Node-ID 0x28";
CM_ BO_ 1960 "Bootloader receive by node MDB4 with Node-ID 0x28";
CM_ BO_ 169 "Emergency message of node MDB5 with Node-ID 0x29";
CM_ BO_ 425 "Transmit PDO 1 of node MDB5 with Node-ID 0x29";
CM_ BO_ 489 "Receive PDO 1 of node MDB5 with Node-ID 0x29";
CM_ BO_ 553 "Transmit PDO 2 of node MDB5 with Node-ID 0x29";
CM_ BO_ 617 "Receive PDO 2 of node MDB5 with Node-ID 0x29";
CM_ BO_ 681 "Transmit PDO 3 of node MDB5 with Node-ID 0x29";
CM_ BO_ 745 "Receive PDO 3 of node MDB5 with Node-ID 0x29";
CM_ BO_ 809 "Transmit PDO 4 of node MDB5 with Node-ID 0x29";
CM_ BO_ 873 "Receive PDO 4 of node MDB5 with Node-ID 0x29";
CM_ BO_ 937 "Transmit PDO 5 of node MDB5 with Node-ID 0x29";
CM_ BO_ 1001 "Transmit PDO 6 of node MDB5 with Node-ID 0x29";
CM_ BO_ 1065 "Transmit PDO 7 of node MDB5 with Node-ID 0x29";
CM_ BO_ 1129 "Transmit PDO 8 of node MDB5 with Node-ID 0x29";
CM_ BO_ 1193 "Transmit PDO 9 of node MDB5 with Node-ID 0x29";
CM_ BO_ 1257 "Transmit PDO 10 of node MDB5 with Node-ID 0x29";
CM_ BO_ 1321 "Transmit PDO 11 of node MDB5 with Node-ID 0x29";
CM_ BO_ 1385 "Transmit PDO 12 of node MDB5 with Node-ID 0x29";
CM_ BO_ 1449 "DO NOT CHANGE ANYTHING HERE!
SDO Response of node MDB5 with Node-ID 0x29";
CM_ SG_ 1449 MDB5_SDO_RespCode "Response code of SDO access.";
CM_ SG_ 1449 MDB5_SDO_ID "Specifies SDO-ID of MDB5";
CM_ BO_ 1513 "DO NOT CHANGE ANYTHING HERE!
SDO Request Upload to node MDB5 with Node-ID 0x29";
CM_ SG_ 1513 MDB5_SDO_ID "Specifies SDO-ID of MDB5";
CM_ BO_ 1577 "DO NOT CHANGE ANYTHING HERE!
SDO Request Download from node MDB5 with Node-ID 0x29";
CM_ SG_ 1577 MDB5_SDO_ID "Specifies SDO-ID of MDB5";
CM_ BO_ 1833 "Heartbeat of node MDB5 with Node-ID 0x29";
CM_ SG_ 1833 MDB5_NodeState "Heartbeat status of node MDB5";
CM_ BO_ 1897 "Bootloader transmit from node MDB5 with Node-ID 0x29";
CM_ BO_ 1961 "Bootloader receive by node MDB5 with Node-ID 0x29";
CM_ BO_ 177 "Emergency message of node MDB6 with Node-ID 0x31";
CM_ BO_ 433 "Transmit PDO 1 of node MDB6 with Node-ID 0x31";
CM_ BO_ 497 "Receive PDO 1 of node MDB6 with Node-ID 0x31";
CM_ BO_ 561 "Transmit PDO 2 of node MDB6 with Node-ID 0x31";
CM_ BO_ 625 "Receive PDO 2 of node MDB6 with Node-ID 0x31";
CM_ BO_ 689 "Transmit PDO 3 of node MDB6 with Node-ID 0x31";
CM_ BO_ 753 "Receive PDO 3 of node MDB6 with Node-ID 0x31";
CM_ BO_ 817 "Transmit PDO 4 of node MDB6 with Node-ID 0x31";
CM_ BO_ 881 "Receive PDO 4 of node MDB6 with Node-ID 0x31";
CM_ BO_ 945 "Transmit PDO 5 of node MDB6 with Node-ID 0x31";
CM_ BO_ 1009 "Transmit PDO 6 of node MDB6 with Node-ID 0x31";
CM_ BO_ 1073 "Transmit PDO 7 of node MDB6 with Node-ID 0x31";
CM_ BO_ 1137 "Transmit PDO 8 of node MDB6 with Node-ID 0x31";
CM_ BO_ 1201 "Transmit PDO 9 of node MDB6 with Node-ID 0x31";
CM_ BO_ 1265 "Transmit PDO 10 of node MDB6 with Node-ID 0x31";
CM_ BO_ 1329 "Transmit PDO 11 of node MDB6 with Node-ID 0x31";
CM_ BO_ 1393 "Transmit PDO 12 of node MDB6 with Node-ID 0x31";
CM_ BO_ 1457 "DO NOT CHANGE ANYTHING HERE!
SDO Response of node MDB6 with Node-ID 0x31";
CM_ SG_ 1457 MDB6_SDO_RespCode "Response code of SDO access.";
CM_ SG_ 1457 MDB6_SDO_ID "Specifies SDO-ID of MDB6";
CM_ BO_ 1521 "DO NOT CHANGE ANYTHING HERE!
SDO Request Upload to node MDB6 with Node-ID 0x31";
CM_ SG_ 1521 MDB6_SDO_ID "Specifies SDO-ID of MDB6";
CM_ BO_ 1585 "DO NOT CHANGE ANYTHING HERE!
SDO Request Download from node MDB6 with Node-ID 0x31";
CM_ SG_ 1585 MDB6_SDO_ID "Specifies SDO-ID of MDB6";
CM_ BO_ 1841 "Heartbeat of node MDB6 with Node-ID 0x31";
CM_ SG_ 1841 MDB6_NodeState "Heartbeat status of node MDB6";
CM_ BO_ 1905 "Bootloader transmit from node MDB6 with Node-ID 0x31";
CM_ BO_ 1969 "Bootloader receive by node MDB6 with Node-ID 0x31";
CM_ BO_ 178 "Emergency message of node Track with Node-ID 0x32";
CM_ BO_ 434 "Transmit PDO 1 of node Track with Node-ID 0x32";
CM_ BO_ 498 "Receive PDO 1 of node Track with Node-ID 0x32";
CM_ BO_ 562 "Transmit PDO 2 of node Track with Node-ID 0x32";
CM_ BO_ 626 "Receive PDO 2 of node Track with Node-ID 0x32";
CM_ BO_ 690 "Transmit PDO 3 of node Track with Node-ID 0x32";
CM_ BO_ 754 "Receive PDO 3 of node Track with Node-ID 0x32";
CM_ BO_ 818 "Transmit PDO 4 of node Track with Node-ID 0x32";
CM_ BO_ 882 "Receive PDO 4 of node Track with Node-ID 0x32";
CM_ BO_ 946 "Transmit PDO 5 of node Track with Node-ID 0x32";
CM_ BO_ 1010 "Transmit PDO 6 of node Track with Node-ID 0x32";
CM_ BO_ 1074 "Transmit PDO 7 of node Track with Node-ID 0x32";
CM_ BO_ 1138 "Transmit PDO 8 of node Track with Node-ID 0x32";
CM_ BO_ 1202 "Transmit PDO 9 of node Track with Node-ID 0x32";
CM_ BO_ 1266 "Transmit PDO 10 of node Track with Node-ID 0x32";
CM_ BO_ 1330 "Transmit PDO 11 of node Track with Node-ID 0x32";
CM_ BO_ 1394 "Transmit PDO 12 of node Track with Node-ID 0x32";
CM_ BO_ 1458 "DO NOT CHANGE ANYTHING HERE!
SDO Response of node Track with Node-ID 0x32";
CM_ SG_ 1458 Track_SDO_RespCode "Response code of SDO access.";
CM_ SG_ 1458 Track_SDO_ID "Specifies SDO-ID of Track";
CM_ BO_ 1522 "DO NOT CHANGE ANYTHING HERE!
SDO Request Upload to node Track with Node-ID 0x32";
CM_ SG_ 1522 Track_SDO_ID "Specifies SDO-ID of Track";
CM_ BO_ 1586 "DO NOT CHANGE ANYTHING HERE!
SDO Request Download from node Track with Node-ID 0x32";
CM_ SG_ 1586 Track_SDO_ID "Specifies SDO-ID of Track";
CM_ BO_ 1842 "Heartbeat of node Track with Node-ID 0x32";
CM_ SG_ 1842 Track_NodeState "Heartbeat status of node Track";
CM_ BO_ 1906 "Bootloader transmit from node Track with Node-ID 0x32";
CM_ BO_ 1970 "Bootloader receive by node Track with Node-ID 0x32";
CM_ BO_ 148 "Emergency message of node CLU with Node-ID 0x14";
CM_ BO_ 404 "Transmit PDO 1 of node CLU with Node-ID 0x14";
CM_ BO_ 468 "Receive PDO 1 of node CLU with Node-ID 0x14";
CM_ BO_ 532 "Transmit PDO 2 of node CLU with Node-ID 0x14";
CM_ BO_ 596 "Receive PDO 2 of node CLU with Node-ID 0x14";
CM_ BO_ 660 "Transmit PDO 3 of node CLU with Node-ID 0x14";
CM_ BO_ 724 "Receive PDO 3 of node CLU with Node-ID 0x14";
CM_ BO_ 788 "Transmit PDO 4 of node CLU with Node-ID 0x14";
CM_ BO_ 852 "Receive PDO 4 of node CLU with Node-ID 0x14";
CM_ BO_ 916 "Transmit PDO 5 of node CLU with Node-ID 0x14";
CM_ BO_ 980 "Transmit PDO 6 of node CLU with Node-ID 0x14";
CM_ BO_ 1044 "Transmit PDO 7 of node CLU with Node-ID 0x14";
CM_ BO_ 1108 "Transmit PDO 8 of node CLU with Node-ID 0x14";
CM_ BO_ 1172 "Transmit PDO 9 of node CLU with Node-ID 0x14";
CM_ BO_ 1236 "Transmit PDO 10 of node CLU with Node-ID 0x14";
CM_ BO_ 1300 "Transmit PDO 11 of node CLU with Node-ID 0x14";
CM_ BO_ 1364 "Transmit PDO 12 of node CLU with Node-ID 0x14";
CM_ BO_ 1428 "DO NOT CHANGE ANYTHING HERE!
SDO Response of node CLU with Node-ID 0x14";
CM_ SG_ 1428 CLU_SDO_ID "Specifies SDO-ID of CLU";
CM_ BO_ 1492 "DO NOT CHANGE ANYTHING HERE!
SDO Request Upload to node CLU with Node-ID 0x14";
CM_ SG_ 1492 CLU_SDO_ID "Specifies SDO-ID of CLU";
CM_ BO_ 1556 "DO NOT CHANGE ANYTHING HERE!
SDO Request Download from node CLU with Node-ID 0x14";
CM_ SG_ 1556 CLU_SDO_ID "Specifies SDO-ID of CLU";
CM_ BO_ 1812 "Heartbeat of node CLU with Node-ID 0x14";
CM_ SG_ 1812 CLU_NodeState "Heartbeat status of node CLU";
CM_ BO_ 1876 "Bootloader transmit from node CLU with Node-ID 0x14";
CM_ BO_ 1940 "Bootloader receive by node CLU with Node-ID 0x14";
BA_DEF_ SG_  "GenSigSendType" ENUM  "Cyclic","OnWrite","OnWriteWithRepetition","OnChange","OnChangeWithRepetition","IfActive","IfActiveWithRepetition","NoSigSendType";
BA_DEF_ BO_  "GenMsgSendType" ENUM  "Cyclic","not_used","not_used","not_used","not_used","Cyclic","not_used","IfActive","NoMsgSendType";
BA_DEF_  "BusType" STRING ;
BA_DEF_  "DBName" STRING ;
BA_DEF_ BO_  "GenMsgCycleTime" INT 2 50000;
BA_DEF_ BO_  "GenMsgDelayTime" INT 1 1000;
BA_DEF_ BO_  "GenMsgNrOfRepetitions" INT 1 999999;
BA_DEF_ SG_  "GenSigStartValue" FLOAT 0 100000000000;
BA_DEF_  "CANzero_ProtocolVersion" STRING ;
BA_DEF_  "CANzero_DBCVersion" INT 0 16777215;
BA_DEF_  "CANzero_SDOClientName" STRING ;
BA_DEF_  "CANzero_NMTMasterName" STRING ;
BA_DEF_ BU_  "CANzero_NodeID" HEX 0 63;
BA_DEF_ SG_  "CANzero_SDO_AccessType" ENUM  "Read Write","Read Only","Write Only";
BA_DEF_DEF_  "GenSigSendType" "Cyclic";
BA_DEF_DEF_  "GenMsgSendType" "NoMsgSendType";
BA_DEF_DEF_  "BusType" "";
BA_DEF_DEF_  "DBName" "";
BA_DEF_DEF_  "GenMsgCycleTime" 100;
BA_DEF_DEF_  "GenMsgDelayTime" 1;
BA_DEF_DEF_  "GenMsgNrOfRepetitions" 1;
BA_DEF_DEF_  "GenSigStartValue" 0;
BA_DEF_DEF_  "CANzero_ProtocolVersion" "";
BA_DEF_DEF_  "CANzero_DBCVersion" 0;
BA_DEF_DEF_  "CANzero_SDOClientName" "Master";
BA_DEF_DEF_  "CANzero_NMTMasterName" "Master";
BA_DEF_DEF_  "CANzero_NodeID" 0;
BA_DEF_DEF_  "CANzero_SDO_AccessType" "Read Write";
BA_ "CANzero_SDOClientName" "TelemetryNode";
BA_ "CANzero_DBCVersion" 205;
BA_ "CANzero_ProtocolVersion" "V1.0";
BA_ "BusType" "CAN";
BA_ "DBName" "pod2022";
BA_ "CANzero_NodeID" BU_ TelemetryNode 34;
BA_ "CANzero_NodeID" BU_ SensorF 1;
BA_ "CANzero_NodeID" BU_ SensorR 2;
BA_ "CANzero_NodeID" BU_ BrakeF 17;
BA_ "CANzero_NodeID" BU_ BrakeR 18;
BA_ "CANzero_NodeID" BU_ PDU 26;
BA_ "CANzero_NodeID" BU_ MDB1 33;
BA_ "CANzero_NodeID" BU_ MDB2 35;
BA_ "CANzero_NodeID" BU_ MDB3 39;
BA_ "CANzero_NodeID" BU_ MDB4 40;
BA_ "CANzero_NodeID" BU_ MDB5 41;
BA_ "CANzero_NodeID" BU_ MDB6 49;
BA_ "CANzero_NodeID" BU_ Track 50;
BA_ "CANzero_NodeID" BU_ CLU 20;
BA_ "GenSigStartValue" SG_ 1041 BrakeF_TX_Pressure_Reservoir 400;
BA_ "GenSigStartValue" SG_ 1089 SensorF_TX_BatteryTemp 600;
BA_ "GenSigStartValue" SG_ 1153 SensorF_Cooling_Temp 600;
BA_ "GenSigStartValue" SG_ 1153 SensorF_LIMT_Stator_4 266.666666666667;
BA_ "GenSigStartValue" SG_ 1153 SensorF_LIMT_Stator_3 266.666666666667;
BA_ "GenSigStartValue" SG_ 1153 SensorF_LIMT_Stator_2 266.666666666667;
BA_ "GenSigStartValue" SG_ 1153 SensorF_LIMT_Stator_1 266.666666666667;
BA_ "GenSigStartValue" SG_ 1154 SensorR_LIMT_Coil_3 50;
BA_ "GenSigStartValue" SG_ 1154 SensorR_LIMT_Coil_2 50;
BA_ "GenSigStartValue" SG_ 1154 SensorR_LIMT_Coil_1 50;
BA_ "GenSigStartValue" SG_ 1106 BrakeR_TX_Pressure_Tank 400;
BA_ "GenSigStartValue" SG_ 1106 BrakeR_TX_Pressure_Retract 400;
BA_ "GenSigStartValue" SG_ 1106 BrakeR_TX_Pressure_Act 400;
BA_ "GenSigStartValue" SG_ 602 PDU_LPCh9_Dutycycle 200;
BA_ "GenSigStartValue" SG_ 602 PDU_LPCh8_Dutycycle 200;
BA_ "GenSigStartValue" SG_ 602 PDU_LPCh3_Dutycycle 200;
BA_ "GenSigStartValue" SG_ 602 PDU_LPCh2_Dutycycle 200;
BA_ "GenSigStartValue" SG_ 602 PDU_LPCh10_Dutycycle 200;
BA_ "GenSigStartValue" SG_ 602 PDU_LPCh1_Dutycycle 200;
BA_ "GenSigStartValue" SG_ 730 PDU_D4_Dutycycle 200;
BA_ "GenSigStartValue" SG_ 730 PDU_D3_Dutycycle 200;
BA_ "GenSigStartValue" SG_ 730 PDU_D2_Dutycycle 200;
BA_ "GenSigStartValue" SG_ 730 PDU_D1_Dutycycle 200;
BA_ "GenSigStartValue" SG_ 730 PDU_HPCh2_Dutycycle 200;
BA_ "GenSigStartValue" SG_ 730 PDU_HPCh1_Dutycycle 200;
VAL_ 2684354556 OpticalSensor_TX_LEDStatus 2 "FLASHING" 1 "ON" 0 "OFF" ;
VAL_ 2 CANzero_NMT_Node 0 "All" 1 "SensorF" 2 "SensorR" 17 "BrakeF" 18 "BrakeR" 26 "PDU" 10 "HVCU" 25 "HVTU" 34 "TelemetryNode" 33 "MDB1" 35 "MDB2" 39 "MDB3" 40 "MDB4" 41 "MDB5" 49 "MDB6" 50 "Track" 20 "CLU" ;
VAL_ 2 CANzero_NMT_State 1 "Start Remote Node" 2 "Stop Remote Node" 128 "Enter Pre-Operational" 129 "Reset" ;
VAL_ 385 SensorF_TX_PodState 14 "Pod Startup" 13 "Pod Pushable" 12 "Pod Safe to Approch" 11 "Pod End Of Run" 10 "Pod Engage Brakes" 9 "Pod Rolling" 8 "Pod Stop Levitation" 7 "Pod Disengage Brakes" 6 "Pod Crusing" 5 "Pod Stable Levitation" 4 "Pod Start Levitation" 3 "Pod Ready to Launch" 2 "Pod Launch Preparation" 1 "Pod Idle" 0 "Pod Off" ;
VAL_ 513 SensorF_TX_PreopHVCUT 1 "Transition" 0 "No Transitions" ;
VAL_ 513 SensorF_TX_PreopPDUT 1 "Transition" 0 "No Transitions" ;
VAL_ 513 SensorF_TX_PreopBrakeRT 1 "Transition" 0 "No Transitions" ;
VAL_ 513 SensorF_TX_PreopBrakeFT 1 "Transition" 0 "No Transitions" ;
VAL_ 513 SensorF_TX_PreopSensorRT 1 "Transition" 0 "No Transitions" ;
VAL_ 513 SensorF_TX_EnableSensorRT 1 "Transition" 0 "No Transitions" ;
VAL_ 513 SensorF_TX_EnablePDUT 1 "Transition" 0 "No Transitions" ;
VAL_ 513 SensorF_TX_EnableHVCUT 1 "Transition" 0 "No Transitions" ;
VAL_ 513 SensorF_TX_EnableBrakeRT 1 "Transition" 0 "No Transitions" ;
VAL_ 513 SensorF_TX_EnableBrakeFT 1 "Transition" 0 "No Transitions" ;
VAL_ 513 SensorF_TX_SetHVTransition 1 "Transition" 0 "No Transitions" ;
VAL_ 513 SensorF_TX_PreopTransition 1 "Transition" 0 "No Transitions" ;
VAL_ 513 SensorF_TX_LaunchStartTransition 1 "Transition" 0 "No Transitions" ;
VAL_ 513 SensorF_TX_LaunchSetupTransition 1 "Transition" 0 "No Transitions" ;
VAL_ 513 SensorF_TX_HWEnableTransition 1 "Transition" 0 "No Transitions" ;
VAL_ 513 SensorF_TX_ErrorResetTransition 1 "Transition" 0 "No Transitions" ;
VAL_ 513 SensorF_TX_EnableTransition 1 "Transition" 0 "No Transitions" ;
VAL_ 513 SensorF_TX_BrakesTransition 1 "Transition" 0 "No Transitions" ;
VAL_ 1409 SensorF_SDO_RespCode 5 "ERR: Out of range" 4 "ERR: No access in this state" 3 "ERR: Read only object" 2 "ERR: Write only object" 1 "ERR: Non existing object" 0 "OK" ;
VAL_ 1409 SensorF_SDO_ID 0 "Reserved" ;
VAL_ 1473 SensorF_SDO_ID 0 "Reserved" ;
VAL_ 1537 SensorF_SDO_ID 0 "Reserved" ;
VAL_ 1793 SensorF_NodeState 0 "Bootup" 4 "Stopped" 5 "Operational" 127 "Pre-Operational" ;
VAL_ 514 SensorR_TX_ErrorFlag 1 "Error" 0 "No Error" ;
VAL_ 514 SensorR_TX_Enabled 1 "Enabled" 0 "Disabled" ;
VAL_ 514 SensorR_TX_TrajectorySet 2 "Invalid set" 1 "Set" 0 "Not set" ;
VAL_ 514 SensorR_TX_RunState 4 "Idle not ready" 3 "Launch Abort" 2 "Finished" 1 "Ready to Launch" 0 "Launching" ;
VAL_ 706 SensorR_RX_ErrorReset 1 "Reset" 0 "No Reset" ;
VAL_ 706 SensorR_RX_Enable 1 "Enable" 0 "Disable" ;
VAL_ 706 SensorR_RX_LaunchComm 2 "No Start" 1 "Abort Launch" 0 "Start Launch" ;
VAL_ 1410 SensorR_SDO_RespCode 5 "ERR: Out of range" 4 "ERR: No access in this state" 3 "ERR: Read only object" 2 "ERR: Write only object" 1 "ERR: Non existing object" 0 "OK" ;
VAL_ 1410 SensorR_SDO_ID 0 "Reserved" ;
VAL_ 1474 SensorR_SDO_ID 0 "Reserved" ;
VAL_ 1538 SensorR_SDO_ID 0 "Reserved" ;
VAL_ 1794 SensorR_NodeState 0 "Bootup" 4 "Stopped" 5 "Operational" 127 "Pre-Operational" ;
VAL_ 401 BrakeF_TX_SDC_Input 1 "Closed" 0 "Open" ;
VAL_ 401 BrakeF_TX_ErrorFlag 1 "Error" 0 "No Error" ;
VAL_ 401 BrakeF_TX_Enabled 1 "Enabled" 0 "Disabled" ;
VAL_ 401 BrakeF_TX_Status 2 "EngagedService" 1 "EngagedEmergency" 0 "Disengaged" ;
VAL_ 465 BrakeF_RX_Engage 2 "EngageService" 1 "EngageEmergency" 0 "Disengage" ;
VAL_ 465 BrakeF_RX_Enable 1 "Enable" 0 "Disable" ;
VAL_ 465 BrakeF_RX_ErrorReset 1 "Reset" 0 "No Reset" ;
VAL_ 1425 BrakeF_SDO_RespCode 5 "ERR: Out of range" 4 "ERR: No access in this state" 3 "ERR: Read only object" 2 "ERR: Write only object" 1 "ERR: Non existing object" 0 "OK" ;
VAL_ 1425 BrakeF_SDO_ID 0 "Reserved" ;
VAL_ 1489 BrakeF_SDO_ID 0 "Reserved" ;
VAL_ 1553 BrakeF_SDO_ID 0 "Reserved" ;
VAL_ 1809 BrakeF_NodeState 0 "Bootup" 4 "Stopped" 5 "Operational" 127 "Pre-Operational" ;
VAL_ 402 BrakeR_TX_SDC_Input 1 "Closed" 0 "Open" ;
VAL_ 402 BrakeR_TX_ErrorFlag 1 "Error" 0 "No Error" ;
VAL_ 402 BrakeR_TX_Enabled 1 "Enabled" 0 "Disabled" ;
VAL_ 402 BrakeR_TX_Status 2 "EngagedService" 1 "EngagedEmergency" 0 "Disengaged" ;
VAL_ 466 BrakeR_RX_Engage 2 "EngageService" 1 "EngageEmergency" 0 "Disengage" ;
VAL_ 466 BrakeR_RX_Enable 1 "Enable" 0 "Disable" ;
VAL_ 466 BrakeR_RX_ErrorReset 1 "Reset" 0 "No Reset" ;
VAL_ 1426 BrakeR_SDO_RespCode 5 "ERR: Out of range" 4 "ERR: No access in this state" 3 "ERR: Read only object" 2 "ERR: Write only object" 1 "ERR: Non existing object" 0 "OK" ;
VAL_ 1426 BrakeR_SDO_ID 0 "Reserved" ;
VAL_ 1490 BrakeR_SDO_ID 0 "Reserved" ;
VAL_ 1554 BrakeR_SDO_ID 0 "Reserved" ;
VAL_ 1810 BrakeR_NodeState 0 "Bootup" 4 "Stopped" 5 "Operational" 127 "Pre-Operational" ;
VAL_ 410 PDU_TX_PEHWEnabled 1 "Enabled" 0 "Disabled" ;
VAL_ 410 PDU_TX_ErrorFlag 1 "Error" 0 "No Error" ;
VAL_ 410 PDU_TX_Enabled 1 "Enabled" 0 "Disabled" ;
VAL_ 474 PDU_RX_PEHWEnable 1 "Enable" 0 "Disable" ;
VAL_ 474 PDU_RX_ErrorReset 1 "Reset" 0 "No Reset" ;
VAL_ 474 PDU_RX_Enable 1 "Enable" 0 "Disable" ;
VAL_ 1178 PDU_LPCh1_State 3 "External Voltage" 2 "Output Short Circuit" 1 "Status Change Pending" 0 "OK" ;
VAL_ 1434 PDU_SDO_RespCode 5 "ERR: Out of range" 4 "ERR: No access in this state" 3 "ERR: Read only object" 2 "ERR: Write only object" 1 "ERR: Non existing object" 0 "OK" ;
VAL_ 1434 PDU_SDO_ID 0 "Reserved" ;
VAL_ 1498 PDU_SDO_ID 0 "Reserved" ;
VAL_ 1562 PDU_SDO_ID 0 "Reserved" ;
VAL_ 1818 PDU_NodeState 0 "Bootup" 4 "Stopped" 5 "Operational" 127 "Pre-Operational" ;
VAL_ 482 TelemetryNode_RX_Shutdown 2 "Reboot" 1 "Shutdown" 0 "None" ;
VAL_ 1442 TelemetryNode_SDO_RespCode 5 "ERR: Out of range" 4 "ERR: No access in this state" 3 "ERR: Read only object" 2 "ERR: Write only object" 1 "ERR: Non existing object" 0 "OK" ;
VAL_ 1442 TelemetryNode_SDO_ID 0 "Reserved" ;
VAL_ 1506 TelemetryNode_SDO_ID 0 "Reserved" ;
VAL_ 1570 TelemetryNode_SDO_ID 0 "Reserved" ;
VAL_ 1826 TelemetryNode_NodeState 0 "Bootup" 4 "Stopped" 5 "Operational" 127 "Pre-Operational" ;
VAL_ 1441 MDB1_SDO_RespCode 5 "ERR: Out of range" 4 "ERR: No access in this state" 3 "ERR: Read only object" 2 "ERR: Write only object" 1 "ERR: Non existing object" 0 "OK" ;
VAL_ 1441 MDB1_SDO_ID 0 "Reserved" ;
VAL_ 1505 MDB1_SDO_ID 0 "Reserved" ;
VAL_ 1569 MDB1_SDO_ID 0 "Reserved" ;
VAL_ 1825 MDB1_NodeState 0 "Bootup" 4 "Stopped" 5 "Operational" 127 "Pre-Operational" ;
VAL_ 1443 MDB2_SDO_RespCode 5 "ERR: Out of range" 4 "ERR: No access in this state" 3 "ERR: Read only object" 2 "ERR: Write only object" 1 "ERR: Non existing object" 0 "OK" ;
VAL_ 1443 MDB2_SDO_ID 0 "Reserved" ;
VAL_ 1507 MDB2_SDO_ID 0 "Reserved" ;
VAL_ 1571 MDB2_SDO_ID 0 "Reserved" ;
VAL_ 1827 MDB2_NodeState 0 "Bootup" 4 "Stopped" 5 "Operational" 127 "Pre-Operational" ;
VAL_ 1447 MDB3_SDO_RespCode 5 "ERR: Out of range" 4 "ERR: No access in this state" 3 "ERR: Read only object" 2 "ERR: Write only object" 1 "ERR: Non existing object" 0 "OK" ;
VAL_ 1447 MDB3_SDO_ID 0 "Reserved" ;
VAL_ 1511 MDB3_SDO_ID 0 "Reserved" ;
VAL_ 1575 MDB3_SDO_ID 0 "Reserved" ;
VAL_ 1831 MDB3_NodeState 0 "Bootup" 4 "Stopped" 5 "Operational" 127 "Pre-Operational" ;
VAL_ 1448 MDB4_SDO_RespCode 5 "ERR: Out of range" 4 "ERR: No access in this state" 3 "ERR: Read only object" 2 "ERR: Write only object" 1 "ERR: Non existing object" 0 "OK" ;
VAL_ 1448 MDB4_SDO_ID 0 "Reserved" ;
VAL_ 1512 MDB4_SDO_ID 0 "Reserved" ;
VAL_ 1576 MDB4_SDO_ID 0 "Reserved" ;
VAL_ 1832 MDB4_NodeState 0 "Bootup" 4 "Stopped" 5 "Operational" 127 "Pre-Operational" ;
VAL_ 1449 MDB5_SDO_RespCode 5 "ERR: Out of range" 4 "ERR: No access in this state" 3 "ERR: Read only object" 2 "ERR: Write only object" 1 "ERR: Non existing object" 0 "OK" ;
VAL_ 1449 MDB5_SDO_ID 0 "Reserved" ;
VAL_ 1513 MDB5_SDO_ID 0 "Reserved" ;
VAL_ 1577 MDB5_SDO_ID 0 "Reserved" ;
VAL_ 1833 MDB5_NodeState 0 "Bootup" 4 "Stopped" 5 "Operational" 127 "Pre-Operational" ;
VAL_ 1457 MDB6_SDO_RespCode 5 "ERR: Out of range" 4 "ERR: No access in this state" 3 "ERR: Read only object" 2 "ERR: Write only object" 1 "ERR: Non existing object" 0 "OK" ;
VAL_ 1457 MDB6_SDO_ID 0 "Reserved" ;
VAL_ 1521 MDB6_SDO_ID 0 "Reserved" ;
VAL_ 1585 MDB6_SDO_ID 0 "Reserved" ;
VAL_ 1841 MDB6_NodeState 0 "Bootup" 4 "Stopped" 5 "Operational" 127 "Pre-Operational" ;
VAL_ 1458 Track_SDO_RespCode 5 "ERR: Out of range" 4 "ERR: No access in this state" 3 "ERR: Read only object" 2 "ERR: Write only object" 1 "ERR: Non existing object" 0 "OK" ;
VAL_ 1458 Track_SDO_ID 0 "Reserved" ;
VAL_ 1522 Track_SDO_ID 0 "Reserved" ;
VAL_ 1586 Track_SDO_ID 0 "Reserved" ;
VAL_ 1842 Track_NodeState 0 "Bootup" 4 "Stopped" 5 "Operational" 127 "Pre-Operational" ;
VAL_ 1428 CLU_SDO_ID 0 "Reserved" ;
VAL_ 1492 CLU_SDO_ID 0 "Reserved" ;
VAL_ 1556 CLU_SDO_ID 0 "Reserved" ;
VAL_ 1812 CLU_NodeState 0 "Bootup" 4 "Stopped" 5 "Operational" 127 "Pre-Operational" ;
